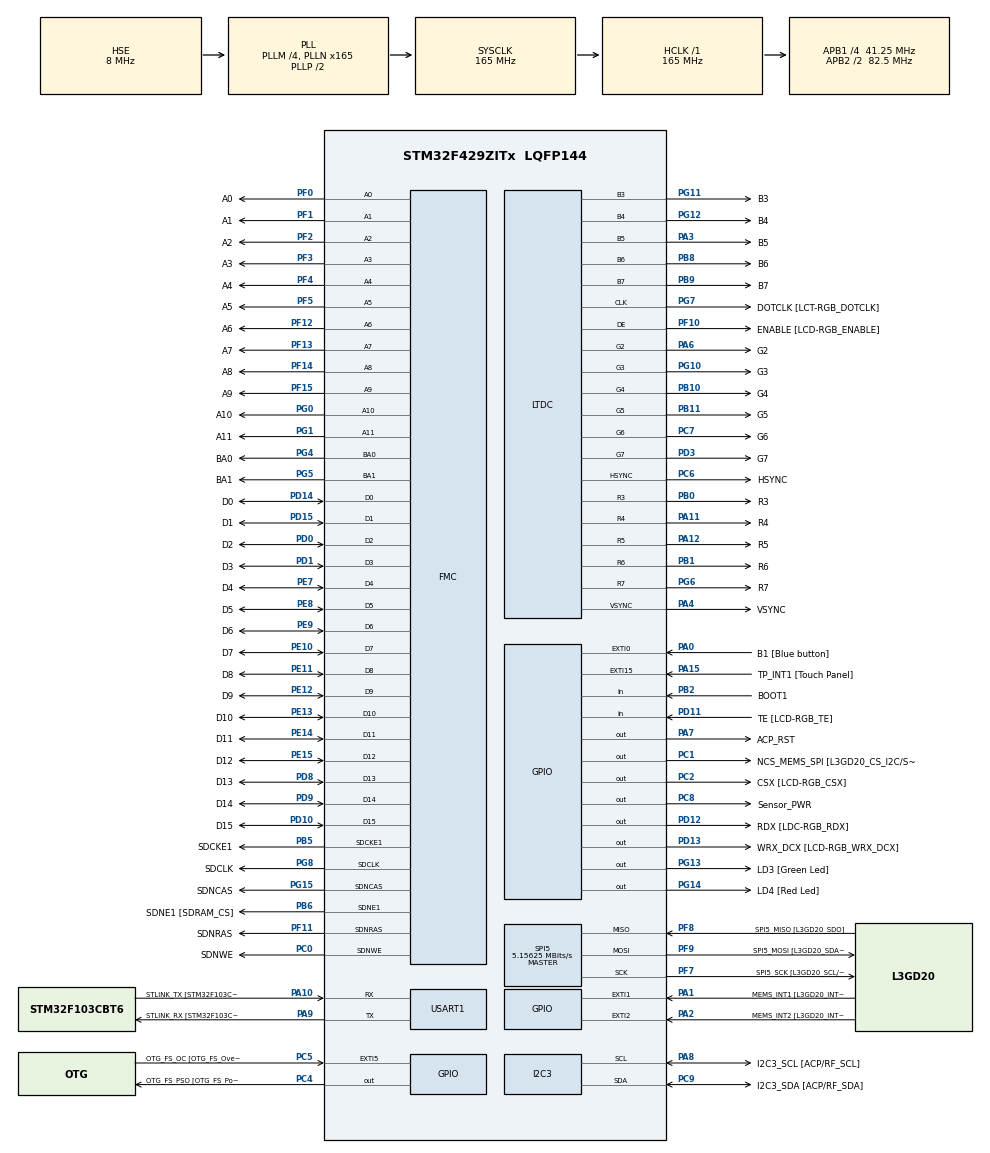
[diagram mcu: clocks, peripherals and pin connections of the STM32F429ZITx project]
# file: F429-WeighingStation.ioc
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Dma.I2C3_RX.0.Direction=DMA_PERIPH_TO_MEMORY
Dma.I2C3_RX.0.FIFOMode=DMA_FIFOMODE_DISABLE
Dma.I2C3_RX.0.Instance=DMA1_Stream2
Dma.I2C3_RX.0.MemDataAlignment=DMA_MDATAALIGN_BYTE
Dma.I2C3_RX.0.MemInc=DMA_MINC_ENABLE
Dma.I2C3_RX.0.Mode=DMA_NORMAL
Dma.I2C3_RX.0.PeriphDataAlignment=DMA_PDATAALIGN_BYTE
Dma.I2C3_RX.0.PeriphInc=DMA_PINC_DISABLE
Dma.I2C3_RX.0.Priority=DMA_PRIORITY_LOW
Dma.I2C3_TX.1.Direction=DMA_MEMORY_TO_PERIPH
Dma.I2C3_TX.1.FIFOMode=DMA_FIFOMODE_DISABLE
Dma.I2C3_TX.1.Instance=DMA1_Stream4
Dma.I2C3_TX.1.MemDataAlignment=DMA_MDATAALIGN_BYTE
Dma.I2C3_TX.1.MemInc=DMA_MINC_ENABLE
Dma.I2C3_TX.1.Mode=DMA_NORMAL
Dma.I2C3_TX.1.PeriphDataAlignment=DMA_PDATAALIGN_BYTE
Dma.I2C3_TX.1.PeriphInc=DMA_PINC_DISABLE
Dma.I2C3_TX.1.Priority=DMA_PRIORITY_LOW
Dma.Request0=I2C3_RX
Dma.Request1=I2C3_TX
Dma.Request2=USART1_RX
Dma.Request3=USART1_TX
Dma.USART1_RX.2.Direction=DMA_PERIPH_TO_MEMORY
Dma.USART1_RX.2.FIFOMode=DMA_FIFOMODE_DISABLE
Dma.USART1_RX.2.Instance=DMA2_Stream2
Dma.USART1_RX.2.MemDataAlignment=DMA_MDATAALIGN_BYTE
Dma.USART1_RX.2.MemInc=DMA_MINC_ENABLE
Dma.USART1_RX.2.Mode=DMA_CIRCULAR
Dma.USART1_RX.2.PeriphDataAlignment=DMA_PDATAALIGN_BYTE
Dma.USART1_RX.2.PeriphInc=DMA_PINC_DISABLE
Dma.USART1_RX.2.Priority=DMA_PRIORITY_MEDIUM
Dma.USART1_TX.3.Direction=DMA_MEMORY_TO_PERIPH
Dma.USART1_TX.3.FIFOMode=DMA_FIFOMODE_DISABLE
Dma.USART1_TX.3.Instance=DMA2_Stream7
Dma.USART1_TX.3.MemDataAlignment=DMA_MDATAALIGN_BYTE
Dma.USART1_TX.3.MemInc=DMA_MINC_ENABLE
Dma.USART1_TX.3.Mode=DMA_NORMAL
Dma.USART1_TX.3.PeriphDataAlignment=DMA_PDATAALIGN_BYTE
Dma.USART1_TX.3.PeriphInc=DMA_PINC_DISABLE
Dma.USART1_TX.3.Priority=DMA_PRIORITY_LOW
FMC.CASLatency1=FMC_SDRAM_CAS_LATENCY_3
FMC.ExitSelfRefreshDelay1=7
FMC.LoadToActiveDelay1=2
FMC.RCDDelay1=2
FMC.RPDelay1=2
FMC.ReadPipeDelay1=FMC_SDRAM_RPIPE_DELAY_1
FMC.RowCycleDelay1=7
FMC.SDClockPeriod1=FMC_SDRAM_CLOCK_PERIOD_2
FMC.SelfRefreshTime1=4
FMC.WriteRecoveryTime1=3
FREERTOS.INCLUDE_xTaskGetCurrentTaskHandle=1
FREERTOS.Tasks01=defaultTask,0,4096,StartDefaultTask,Default,NULL,Dynamic,NULL,NULL;grabI2CTask,-3,512,StartTaskI2C,Default,NULL,Dynamic,NULL,NULL;readI2CTask,0,512,readI2C,Default,NULL,Dynamic,NULL,NULL
FREERTOS.configCHECK_FOR_STACK_OVERFLOW=2
FREERTOS.configENABLE_BACKWARD_COMPATIBILITY=0
FREERTOS.configMINIMAL_STACK_SIZE=512
FREERTOS.configTOTAL_HEAP_SIZE=65536
FREERTOS.configUSE_APPLICATION_TASK_TAG=0
FREERTOS.configUSE_COUNTING_SEMAPHORES=0
FREERTOS.configUSE_IDLE_HOOK=0
FREERTOS.configUSE_MALLOC_FAILED_HOOK=1
FREERTOS.configUSE_RECURSIVE_MUTEXES=0
I2C3.AddressingMode=I2C_ADDRESSINGMODE_7BIT
I2C3.DutyCycle=I2C_DUTYCYCLE_16_9
I2C3.I2C_Mode=I2C_Fast
I2C3.OwnAddress=0x7E
LTDC.ActiveH=320
LTDC.ActiveW=240
LTDC.Alpha_L0=255
LTDC.BlendingFactor1_L0=LTDC_BLENDING_FACTOR1_PAxCA
LTDC.BlendingFactor2_L0=LTDC_BLENDING_FACTOR2_PAxCA
LTDC.FBStartAdress_L0=0xD0000000
LTDC.HBP=20
LTDC.HFP=10
LTDC.HSync=10
LTDC.ImageHeight_L0=320
LTDC.ImageWidth_L0=240
LTDC.Layers=0
LTDC.PixelFormat_L0=LTDC_PIXEL_FORMAT_RGB565
LTDC.VFP=4
LTDC.VSync=2
LTDC.WindowX1_L0=240
LTDC.WindowY1_L0=320
Mcu.Family=STM32F4
Mcu.Name=STM32F429ZITx
Mcu.Package=LQFP144
NVIC.DMA1_Stream2_IRQn=true\:5\:0\:false\:false\:true\:true\:false\:true
NVIC.DMA1_Stream4_IRQn=true\:5\:0\:false\:false\:true\:true\:false\:true
NVIC.DMA2_Stream2_IRQn=true\:5\:0\:true\:false\:true\:true\:false\:true
NVIC.DMA2_Stream7_IRQn=true\:5\:0\:true\:false\:true\:true\:false\:true
NVIC.EXTI0_IRQn=true\:5\:0\:false\:false\:true\:true\:true\:true
NVIC.I2C3_ER_IRQn=true\:5\:0\:false\:false\:true\:true\:true\:true
NVIC.I2C3_EV_IRQn=true\:5\:0\:false\:false\:true\:true\:true\:true
NVIC.LTDC_IRQn=true\:5\:0\:false\:false\:true\:true\:true\:true
NVIC.PriorityGroup=NVIC_PRIORITYGROUP_4
NVIC.TIM6_DAC_IRQn=true\:0\:0\:false\:false\:true\:false\:false\:true
NVIC.TimeBase=TIM6_DAC_IRQn
NVIC.TimeBaseIP=TIM6
NVIC.USART1_IRQn=true\:5\:0\:true\:false\:true\:false\:true\:true
PA0/WKUP.GPIO_Label=B1 [Blue button]
PA0/WKUP.Signal=GPXTI0
PA1.GPIO_Label=MEMS_INT1 [L3GD20_INT1]
PA1.GPIO_ModeDefaultEXTI=GPIO_MODE_EVT_RISING
PA1.GPIO_PuPd=GPIO_NOPULL
PA1.Signal=GPXTI1
PA10.GPIO_Label=STLINK_TX [STM32F103CBT6_PA2]
PA10.Mode=Asynchronous
PA10.Signal=USART1_RX
PA11.GPIO_Label=R4
PA11.GPIO_Mode=GPIO_MODE_AF_PP
PA11.GPIO_PuPd=GPIO_NOPULL
PA11.GPIO_Speed=GPIO_SPEED_FREQ_LOW
PA11.Mode=RGB565
PA11.Signal=LTDC_R4
PA12.GPIO_Label=R5
PA12.GPIO_Mode=GPIO_MODE_AF_PP
PA12.GPIO_PuPd=GPIO_NOPULL
PA12.GPIO_Speed=GPIO_SPEED_FREQ_LOW
PA12.Mode=RGB565
PA12.Signal=LTDC_R5
PA13.GPIO_Label=SWDIO
PA13.Mode=Serial_Wire
PA13.Signal=SYS_JTMS-SWDIO
PA14.GPIO_Label=SWCLK
PA14.Mode=Serial_Wire
PA14.Signal=SYS_JTCK-SWCLK
PA15.GPIO_Label=TP_INT1 [Touch Panel]
PA15.GPIO_ModeDefaultEXTI=GPIO_MODE_EVT_RISING
PA15.GPIO_PuPd=GPIO_NOPULL
PA15.Signal=GPXTI15
PA2.GPIO_Label=MEMS_INT2 [L3GD20_INT2]
PA2.GPIO_ModeDefaultEXTI=GPIO_MODE_EVT_RISING
PA2.GPIO_PuPd=GPIO_NOPULL
PA2.Signal=GPXTI2
PA3.GPIO_Label=B5
PA3.GPIO_Mode=GPIO_MODE_AF_PP
PA3.GPIO_PuPd=GPIO_NOPULL
PA3.GPIO_Speed=GPIO_SPEED_FREQ_LOW
PA3.Mode=RGB565
PA3.Signal=LTDC_B5
PA4.GPIO_Label=VSYNC
PA4.GPIO_Mode=GPIO_MODE_AF_PP
PA4.GPIO_PuPd=GPIO_NOPULL
PA4.GPIO_Speed=GPIO_SPEED_FREQ_LOW
PA4.Mode=RGB565
PA4.Signal=LTDC_VSYNC
PA6.GPIO_Label=G2
PA6.GPIO_Mode=GPIO_MODE_AF_PP
PA6.GPIO_PuPd=GPIO_NOPULL
PA6.GPIO_Speed=GPIO_SPEED_FREQ_LOW
PA6.Mode=RGB565
PA6.Signal=LTDC_G2
PA7.GPIO_Label=ACP_RST
PA7.GPIO_Mode=GPIO_MODE_OUTPUT_PP
PA7.GPIO_PuPd=GPIO_NOPULL
PA7.GPIO_Speed=GPIO_SPEED_FREQ_LOW
PA7.Signal=GPIO_Output
PA8.GPIO_Label=I2C3_SCL [ACP/RF_SCL]
PA8.GPIO_Mode=GPIO_MODE_AF_OD
PA8.GPIO_PuPd=GPIO_NOPULL
PA8.GPIO_Speed=GPIO_SPEED_FREQ_LOW
PA8.Mode=I2C
PA8.Signal=I2C3_SCL
PA9.GPIO_Label=STLINK_RX [STM32F103CBT6_PA3]
PA9.Mode=Asynchronous
PA9.Signal=USART1_TX
PB0.GPIO_Label=R3
PB0.GPIO_Mode=GPIO_MODE_AF_PP
PB0.GPIO_PuPd=GPIO_NOPULL
PB0.GPIO_Speed=GPIO_SPEED_FREQ_LOW
PB0.Mode=RGB565
PB0.Signal=LTDC_R3
PB1.GPIO_Label=R6
PB1.GPIO_Mode=GPIO_MODE_AF_PP
PB1.GPIO_PuPd=GPIO_NOPULL
PB1.GPIO_Speed=GPIO_SPEED_FREQ_LOW
PB1.Mode=RGB565
PB1.Signal=LTDC_R6
PB10.GPIO_Label=G4
PB10.GPIO_Mode=GPIO_MODE_AF_PP
PB10.GPIO_PuPd=GPIO_NOPULL
PB10.GPIO_Speed=GPIO_SPEED_FREQ_LOW
PB10.Mode=RGB565
PB10.Signal=LTDC_G4
PB11.GPIO_Label=G5
PB11.GPIO_Mode=GPIO_MODE_AF_PP
PB11.GPIO_PuPd=GPIO_NOPULL
PB11.GPIO_Speed=GPIO_SPEED_FREQ_LOW
PB11.Mode=RGB565
PB11.Signal=LTDC_G5
PB12.GPIO_Label=OTG_HS_ID
PB12.GPIO_Mode=GPIO_MODE_AF_PP
PB12.GPIO_PuPd=GPIO_NOPULL
PB12.GPIO_Speed=GPIO_SPEED_FREQ_LOW
PB12.Signal=USB_OTG_HS_ID
PB13.GPIO_Label=VBUS_HS
PB13.GPIO_Mode=GPIO_MODE_INPUT
PB13.GPIO_PuPd=GPIO_NOPULL
PB13.Signal=USB_OTG_HS_VBUS
PB14.GPIO_Label=OTG_HS_DM
PB14.GPIO_Mode=GPIO_MODE_AF_PP
PB14.GPIO_PuPd=GPIO_NOPULL
PB14.GPIO_Speed=GPIO_SPEED_FREQ_LOW
PB14.Signal=USB_OTG_HS_DM
PB15.GPIO_Label=OTG_HS_DP
PB15.GPIO_Mode=GPIO_MODE_AF_PP
PB15.GPIO_PuPd=GPIO_NOPULL
PB15.GPIO_Speed=GPIO_SPEED_FREQ_LOW
PB15.Signal=USB_OTG_HS_DP
PB2/BOOT1.GPIO_Label=BOOT1
PB2/BOOT1.GPIO_Mode=GPIO_MODE_INPUT
PB2/BOOT1.GPIO_PuPd=GPIO_NOPULL
PB2/BOOT1.Signal=GPIO_Input
PB5.GPIO_Label=SDCKE1
PB5.GPIO_Mode=GPIO_MODE_AF_PP
PB5.GPIO_PuPd=GPIO_NOPULL
PB5.GPIO_Speed=GPIO_SPEED_FREQ_VERY_HIGH
PB5.Mode=SdramChipSelect2_1
PB5.Signal=FMC_SDCKE1
PB6.GPIO_Label=SDNE1 [SDRAM_CS]
PB6.GPIO_Mode=GPIO_MODE_AF_PP
PB6.GPIO_PuPd=GPIO_NOPULL
PB6.GPIO_Speed=GPIO_SPEED_FREQ_VERY_HIGH
PB6.Mode=SdramChipSelect2_1
PB6.Signal=FMC_SDNE1
PB8.GPIO_Label=B6
PB8.GPIO_Mode=GPIO_MODE_AF_PP
PB8.GPIO_PuPd=GPIO_NOPULL
PB8.GPIO_Speed=GPIO_SPEED_FREQ_LOW
PB8.Mode=RGB565
PB8.Signal=LTDC_B6
PB9.GPIO_Label=B7
PB9.GPIO_Mode=GPIO_MODE_AF_PP
PB9.GPIO_PuPd=GPIO_NOPULL
PB9.GPIO_Speed=GPIO_SPEED_FREQ_LOW
PB9.Mode=RGB565
PB9.Signal=LTDC_B7
PC0.GPIO_Label=SDNWE
PC0.GPIO_Mode=GPIO_MODE_AF_PP
PC0.GPIO_PuPd=GPIO_NOPULL
PC0.GPIO_Speed=GPIO_SPEED_FREQ_VERY_HIGH
PC0.Signal=FMC_SDNWE
PC1.GPIO_Label=NCS_MEMS_SPI [L3GD20_CS_I2C/SPI]
PC1.GPIO_Mode=GPIO_MODE_OUTPUT_PP
PC1.GPIO_PuPd=GPIO_NOPULL
PC1.GPIO_Speed=GPIO_SPEED_FREQ_LOW
PC1.Signal=GPIO_Output
PC10.GPIO_Label=R2
PC10.GPIO_Mode=GPIO_MODE_AF_PP
PC10.GPIO_PuPd=GPIO_NOPULL
PC10.GPIO_Speed=GPIO_SPEED_FREQ_LOW
PC10.Signal=LTDC_R2
PC14/OSC32_IN.GPIO_Label=PC14-OSC32_IN
PC14/OSC32_IN.Signal=RCC_OSC32_IN
PC15/OSC32_OUT.GPIO_Label=PC15-OSC32_OUT
PC15/OSC32_OUT.Signal=RCC_OSC32_OUT
PC2.GPIO_Label=CSX [LCD-RGB_CSX]
PC2.GPIO_Mode=GPIO_MODE_OUTPUT_PP
PC2.GPIO_PuPd=GPIO_NOPULL
PC2.GPIO_Speed=GPIO_SPEED_FREQ_LOW
PC2.Signal=GPIO_Output
PC4.GPIO_Label=OTG_FS_PSO [OTG_FS_PowerSwitchOn]
PC4.GPIO_Mode=GPIO_MODE_OUTPUT_PP
PC4.GPIO_PuPd=GPIO_NOPULL
PC4.GPIO_Speed=GPIO_SPEED_FREQ_LOW
PC4.Signal=GPIO_Output
PC5.GPIO_Label=OTG_FS_OC [OTG_FS_OverCurrent]
PC5.GPIO_ModeDefaultEXTI=GPIO_MODE_EVT_RISING
PC5.Signal=GPXTI5
PC6.GPIO_Label=HSYNC
PC6.GPIO_Mode=GPIO_MODE_AF_PP
PC6.GPIO_PuPd=GPIO_NOPULL
PC6.GPIO_Speed=GPIO_SPEED_FREQ_LOW
PC6.Mode=RGB565
PC6.Signal=LTDC_HSYNC
PC7.GPIO_Label=G6
PC7.GPIO_Mode=GPIO_MODE_AF_PP
PC7.GPIO_PuPd=GPIO_NOPULL
PC7.GPIO_Speed=GPIO_SPEED_FREQ_LOW
PC7.Mode=RGB565
PC7.Signal=LTDC_G6
PC8.GPIO_Label=Sensor_PWR
PC8.Signal=GPIO_Output
PC9.GPIO_Label=I2C3_SDA [ACP/RF_SDA]
PC9.GPIO_Mode=GPIO_MODE_AF_OD
PC9.GPIO_PuPd=GPIO_NOPULL
PC9.GPIO_Speed=GPIO_SPEED_FREQ_LOW
PC9.Mode=I2C
PC9.Signal=I2C3_SDA
PD0.GPIO_Label=D2
PD0.GPIO_Mode=GPIO_MODE_AF_PP
PD0.GPIO_PuPd=GPIO_NOPULL
PD0.GPIO_Speed=GPIO_SPEED_FREQ_VERY_HIGH
PD0.Signal=FMC_D2_DA2
PD1.GPIO_Label=D3
PD1.GPIO_Mode=GPIO_MODE_AF_PP
PD1.GPIO_PuPd=GPIO_NOPULL
PD1.GPIO_Speed=GPIO_SPEED_FREQ_VERY_HIGH
PD1.Signal=FMC_D3_DA3
PD10.GPIO_Label=D15
PD10.GPIO_Mode=GPIO_MODE_AF_PP
PD10.GPIO_PuPd=GPIO_NOPULL
PD10.GPIO_Speed=GPIO_SPEED_FREQ_VERY_HIGH
PD10.Signal=FMC_D15_DA15
PD11.GPIO_Label=TE [LCD-RGB_TE]
PD11.GPIO_Mode=GPIO_MODE_INPUT
PD11.GPIO_PuPd=GPIO_NOPULL
PD11.Signal=GPIO_Input
PD12.GPIO_Label=RDX [LDC-RGB_RDX]
PD12.GPIO_Mode=GPIO_MODE_OUTPUT_PP
PD12.GPIO_PuPd=GPIO_NOPULL
PD12.GPIO_Speed=GPIO_SPEED_FREQ_LOW
PD12.Signal=GPIO_Output
PD13.GPIO_Label=WRX_DCX [LCD-RGB_WRX_DCX]
PD13.GPIO_Mode=GPIO_MODE_OUTPUT_PP
PD13.GPIO_PuPd=GPIO_NOPULL
PD13.GPIO_Speed=GPIO_SPEED_FREQ_LOW
PD13.Signal=GPIO_Output
PD14.GPIO_Label=D0
PD14.GPIO_Mode=GPIO_MODE_AF_PP
PD14.GPIO_PuPd=GPIO_NOPULL
PD14.GPIO_Speed=GPIO_SPEED_FREQ_VERY_HIGH
PD14.Signal=FMC_D0_DA0
PD15.GPIO_Label=D1
PD15.GPIO_Mode=GPIO_MODE_AF_PP
PD15.GPIO_PuPd=GPIO_NOPULL
PD15.GPIO_Speed=GPIO_SPEED_FREQ_VERY_HIGH
PD15.Signal=FMC_D1_DA1
PD3.GPIO_Label=G7
PD3.GPIO_Mode=GPIO_MODE_AF_PP
PD3.GPIO_PuPd=GPIO_NOPULL
PD3.GPIO_Speed=GPIO_SPEED_FREQ_LOW
PD3.Mode=RGB565
PD3.Signal=LTDC_G7
PD6.GPIO_Label=B2
PD6.GPIO_Mode=GPIO_MODE_AF_PP
PD6.GPIO_PuPd=GPIO_NOPULL
PD6.GPIO_Speed=GPIO_SPEED_FREQ_LOW
PD6.Signal=LTDC_B2
PD8.GPIO_Label=D13
PD8.GPIO_Mode=GPIO_MODE_AF_PP
PD8.GPIO_PuPd=GPIO_NOPULL
PD8.GPIO_Speed=GPIO_SPEED_FREQ_VERY_HIGH
PD8.Signal=FMC_D13_DA13
PD9.GPIO_Label=D14
PD9.GPIO_Mode=GPIO_MODE_AF_PP
PD9.GPIO_PuPd=GPIO_NOPULL
PD9.GPIO_Speed=GPIO_SPEED_FREQ_VERY_HIGH
PD9.Signal=FMC_D14_DA14
PE0.GPIO_Label=NBL0 [SDRAM_LDQM]
PE0.GPIO_Mode=GPIO_MODE_AF_PP
PE0.GPIO_PuPd=GPIO_NOPULL
PE0.GPIO_Speed=GPIO_SPEED_FREQ_VERY_HIGH
PE0.Signal=FMC_NBL0
PE1.GPIO_Label=NBL1 [SDRAM_UDQM]
PE1.GPIO_Mode=GPIO_MODE_AF_PP
PE1.GPIO_PuPd=GPIO_NOPULL
PE1.GPIO_Speed=GPIO_SPEED_FREQ_VERY_HIGH
PE1.Signal=FMC_NBL1
PE10.GPIO_Label=D7
PE10.GPIO_Mode=GPIO_MODE_AF_PP
PE10.GPIO_PuPd=GPIO_NOPULL
PE10.GPIO_Speed=GPIO_SPEED_FREQ_VERY_HIGH
PE10.Signal=FMC_D7_DA7
PE11.GPIO_Label=D8
PE11.GPIO_Mode=GPIO_MODE_AF_PP
PE11.GPIO_PuPd=GPIO_NOPULL
PE11.GPIO_Speed=GPIO_SPEED_FREQ_VERY_HIGH
PE11.Signal=FMC_D8_DA8
PE12.GPIO_Label=D9
PE12.GPIO_Mode=GPIO_MODE_AF_PP
PE12.GPIO_PuPd=GPIO_NOPULL
PE12.GPIO_Speed=GPIO_SPEED_FREQ_VERY_HIGH
PE12.Signal=FMC_D9_DA9
PE13.GPIO_Label=D10
PE13.GPIO_Mode=GPIO_MODE_AF_PP
PE13.GPIO_PuPd=GPIO_NOPULL
PE13.GPIO_Speed=GPIO_SPEED_FREQ_VERY_HIGH
PE13.Signal=FMC_D10_DA10
PE14.GPIO_Label=D11
PE14.GPIO_Mode=GPIO_MODE_AF_PP
PE14.GPIO_PuPd=GPIO_NOPULL
PE14.GPIO_Speed=GPIO_SPEED_FREQ_VERY_HIGH
PE14.Signal=FMC_D11_DA11
PE15.GPIO_Label=D12
PE15.GPIO_Mode=GPIO_MODE_AF_PP
PE15.GPIO_PuPd=GPIO_NOPULL
PE15.GPIO_Speed=GPIO_SPEED_FREQ_VERY_HIGH
PE15.Signal=FMC_D12_DA12
PE7.GPIO_Label=D4
PE7.GPIO_Mode=GPIO_MODE_AF_PP
PE7.GPIO_PuPd=GPIO_NOPULL
PE7.GPIO_Speed=GPIO_SPEED_FREQ_VERY_HIGH
PE7.Signal=FMC_D4_DA4
PE8.GPIO_Label=D5
PE8.GPIO_Mode=GPIO_MODE_AF_PP
PE8.GPIO_PuPd=GPIO_NOPULL
PE8.GPIO_Speed=GPIO_SPEED_FREQ_VERY_HIGH
PE8.Signal=FMC_D5_DA5
PE9.GPIO_Label=D6
PE9.GPIO_Mode=GPIO_MODE_AF_PP
PE9.GPIO_PuPd=GPIO_NOPULL
PE9.GPIO_Speed=GPIO_SPEED_FREQ_VERY_HIGH
PE9.Signal=FMC_D6_DA6
PF0.GPIO_Label=A0
PF0.GPIO_Mode=GPIO_MODE_AF_PP
PF0.GPIO_PuPd=GPIO_NOPULL
PF0.GPIO_Speed=GPIO_SPEED_FREQ_VERY_HIGH
PF0.Signal=FMC_A0
PF1.GPIO_Label=A1
PF1.GPIO_Mode=GPIO_MODE_AF_PP
PF1.GPIO_PuPd=GPIO_NOPULL
PF1.GPIO_Speed=GPIO_SPEED_FREQ_VERY_HIGH
PF1.Signal=FMC_A1
PF10.GPIO_Label=ENABLE [LCD-RGB_ENABLE]
PF10.GPIO_Mode=GPIO_MODE_AF_PP
PF10.GPIO_PuPd=GPIO_NOPULL
PF10.GPIO_Speed=GPIO_SPEED_FREQ_LOW
PF10.Mode=RGB565
PF10.Signal=LTDC_DE
PF11.GPIO_Label=SDNRAS
PF11.GPIO_Mode=GPIO_MODE_AF_PP
PF11.GPIO_PuPd=GPIO_NOPULL
PF11.GPIO_Speed=GPIO_SPEED_FREQ_VERY_HIGH
PF11.Signal=FMC_SDNRAS
PF12.GPIO_Label=A6
PF12.GPIO_Mode=GPIO_MODE_AF_PP
PF12.GPIO_PuPd=GPIO_NOPULL
PF12.GPIO_Speed=GPIO_SPEED_FREQ_VERY_HIGH
PF12.Signal=FMC_A6
PF13.GPIO_Label=A7
PF13.GPIO_Mode=GPIO_MODE_AF_PP
PF13.GPIO_PuPd=GPIO_NOPULL
PF13.GPIO_Speed=GPIO_SPEED_FREQ_VERY_HIGH
PF13.Signal=FMC_A7
PF14.GPIO_Label=A8
PF14.GPIO_Mode=GPIO_MODE_AF_PP
PF14.GPIO_PuPd=GPIO_NOPULL
PF14.GPIO_Speed=GPIO_SPEED_FREQ_VERY_HIGH
PF14.Signal=FMC_A8
PF15.GPIO_Label=A9
PF15.GPIO_Mode=GPIO_MODE_AF_PP
PF15.GPIO_PuPd=GPIO_NOPULL
PF15.GPIO_Speed=GPIO_SPEED_FREQ_VERY_HIGH
PF15.Signal=FMC_A9
PF2.GPIO_Label=A2
PF2.GPIO_Mode=GPIO_MODE_AF_PP
PF2.GPIO_PuPd=GPIO_NOPULL
PF2.GPIO_Speed=GPIO_SPEED_FREQ_VERY_HIGH
PF2.Signal=FMC_A2
PF3.GPIO_Label=A3
PF3.GPIO_Mode=GPIO_MODE_AF_PP
PF3.GPIO_PuPd=GPIO_NOPULL
PF3.GPIO_Speed=GPIO_SPEED_FREQ_VERY_HIGH
PF3.Signal=FMC_A3
PF4.GPIO_Label=A4
PF4.GPIO_Mode=GPIO_MODE_AF_PP
PF4.GPIO_PuPd=GPIO_NOPULL
PF4.GPIO_Speed=GPIO_SPEED_FREQ_VERY_HIGH
PF4.Signal=FMC_A4
PF5.GPIO_Label=A5
PF5.GPIO_Mode=GPIO_MODE_AF_PP
PF5.GPIO_PuPd=GPIO_NOPULL
PF5.GPIO_Speed=GPIO_SPEED_FREQ_VERY_HIGH
PF5.Signal=FMC_A5
PF7.GPIO_Label=SPI5_SCK [L3GD20_SCL/SPC]
PF7.GPIO_Mode=GPIO_MODE_AF_PP
PF7.GPIO_PuPd=GPIO_NOPULL
PF7.GPIO_Speed=GPIO_SPEED_FREQ_LOW
PF7.Mode=Full_Duplex_Master
PF7.Signal=SPI5_SCK
PF8.GPIO_Label=SPI5_MISO [L3GD20_SDO]
PF8.GPIO_Mode=GPIO_MODE_AF_PP
PF8.GPIO_PuPd=GPIO_NOPULL
PF8.GPIO_Speed=GPIO_SPEED_FREQ_LOW
PF8.Mode=Full_Duplex_Master
PF8.Signal=SPI5_MISO
PF9.GPIO_Label=SPI5_MOSI [L3GD20_SDA/SDI/SDO]
PF9.GPIO_Mode=GPIO_MODE_AF_PP
PF9.GPIO_PuPd=GPIO_NOPULL
PF9.GPIO_Speed=GPIO_SPEED_FREQ_LOW
PF9.Mode=Full_Duplex_Master
PF9.Signal=SPI5_MOSI
PG0.GPIO_Label=A10
PG0.GPIO_Mode=GPIO_MODE_AF_PP
PG0.GPIO_PuPd=GPIO_NOPULL
PG0.GPIO_Speed=GPIO_SPEED_FREQ_VERY_HIGH
PG0.Signal=FMC_A10
PG1.GPIO_Label=A11
PG1.GPIO_Mode=GPIO_MODE_AF_PP
PG1.GPIO_PuPd=GPIO_NOPULL
PG1.GPIO_Speed=GPIO_SPEED_FREQ_VERY_HIGH
PG1.Signal=FMC_A11
PG10.GPIO_Label=G3
PG10.GPIO_Mode=GPIO_MODE_AF_PP
PG10.GPIO_PuPd=GPIO_NOPULL
PG10.GPIO_Speed=GPIO_SPEED_FREQ_LOW
PG10.Mode=RGB565
PG10.Signal=LTDC_G3
PG11.GPIO_Label=B3
PG11.GPIO_Mode=GPIO_MODE_AF_PP
PG11.GPIO_PuPd=GPIO_NOPULL
PG11.GPIO_Speed=GPIO_SPEED_FREQ_LOW
PG11.Mode=RGB565
PG11.Signal=LTDC_B3
PG12.GPIO_Label=B4
PG12.GPIO_Mode=GPIO_MODE_AF_PP
PG12.GPIO_PuPd=GPIO_NOPULL
PG12.GPIO_Speed=GPIO_SPEED_FREQ_LOW
PG12.Mode=RGB565
PG12.Signal=LTDC_B4
PG13.GPIO_Label=LD3 [Green Led]
PG13.GPIO_Mode=GPIO_MODE_OUTPUT_PP
PG13.GPIO_PuPd=GPIO_NOPULL
PG13.GPIO_Speed=GPIO_SPEED_FREQ_LOW
PG13.Signal=GPIO_Output
PG14.GPIO_Label=LD4 [Red Led]
PG14.GPIO_Mode=GPIO_MODE_OUTPUT_PP
PG14.GPIO_PuPd=GPIO_NOPULL
PG14.GPIO_Speed=GPIO_SPEED_FREQ_LOW
PG14.Signal=GPIO_Output
PG15.GPIO_Label=SDNCAS
PG15.GPIO_Mode=GPIO_MODE_AF_PP
PG15.GPIO_PuPd=GPIO_NOPULL
PG15.GPIO_Speed=GPIO_SPEED_FREQ_VERY_HIGH
PG15.Signal=FMC_SDNCAS
PG4.GPIO_Label=BA0
PG4.GPIO_Mode=GPIO_MODE_AF_PP
PG4.GPIO_PuPd=GPIO_NOPULL
PG4.GPIO_Speed=GPIO_SPEED_FREQ_VERY_HIGH
PG4.Signal=FMC_A14_BA0
PG5.GPIO_Label=BA1
PG5.GPIO_Mode=GPIO_MODE_AF_PP
PG5.GPIO_PuPd=GPIO_NOPULL
PG5.GPIO_Speed=GPIO_SPEED_FREQ_VERY_HIGH
PG5.Signal=FMC_A15_BA1
PG6.GPIO_Label=R7
PG6.GPIO_Mode=GPIO_MODE_AF_PP
PG6.GPIO_PuPd=GPIO_NOPULL
PG6.GPIO_Speed=GPIO_SPEED_FREQ_LOW
PG6.Mode=RGB565
PG6.Signal=LTDC_R7
PG7.GPIO_Label=DOTCLK [LCT-RGB_DOTCLK]
PG7.GPIO_Mode=GPIO_MODE_AF_PP
PG7.GPIO_PuPd=GPIO_NOPULL
PG7.GPIO_Speed=GPIO_SPEED_FREQ_LOW
PG7.Mode=RGB565
PG7.Signal=LTDC_CLK
PG8.GPIO_Label=SDCLK
PG8.GPIO_Mode=GPIO_MODE_AF_PP
PG8.GPIO_PuPd=GPIO_NOPULL
PG8.GPIO_Speed=GPIO_SPEED_FREQ_VERY_HIGH
PG8.Signal=FMC_SDCLK
PH0/OSC_IN.GPIO_Label=PH0-OSC_IN
PH0/OSC_IN.Mode=HSE-External-Oscillator
PH0/OSC_IN.Signal=RCC_OSC_IN
PH1/OSC_OUT.GPIO_Label=PH1-OSC_OUT
PH1/OSC_OUT.Mode=HSE-External-Oscillator
PH1/OSC_OUT.Signal=RCC_OSC_OUT
ProjectManager.HeapSize=0x200
ProjectManager.StackSize=0x400
ProjectManager.TargetToolchain=STM32CubeIDE
RCC.48MHZClocksFreq_Value=47142857.14285714
RCC.AHBFreq_Value=165000000
RCC.APB1CLKDivider=RCC_HCLK_DIV4
RCC.APB1Freq_Value=41250000
RCC.APB1TimFreq_Value=165000000
RCC.APB2CLKDivider=RCC_HCLK_DIV2
RCC.APB2Freq_Value=82500000
RCC.APB2TimFreq_Value=165000000
RCC.CortexFreq_Value=165000000
RCC.HCLKFreq_Value=165000000
RCC.HSE_VALUE=8000000
RCC.HSI_VALUE=16000000
RCC.LSE_VALUE=32768
RCC.PLLM=4
RCC.PLLN=165
RCC.PLLQ=7
RCC.PLLSAIN=50
RCC.PLLSourceVirtual=RCC_PLLSOURCE_HSE
RCC.PWREXT_OverDrive=PWREXT_OverDrive_ACTIVATED
RCC.PWR_Regulator_Voltage_Scale=PWR_REGULATOR_VOLTAGE_SCALE1
RCC.RCC_TIM_PRescaler_Selection=RCC_TIMPRES_ACTIVATED
RCC.SYSCLKFreq_VALUE=165000000
RCC.SYSCLKSource=RCC_SYSCLKSOURCE_PLLCLK
RCC.VCOOutputFreq_Value=330000000
SH.FMC_A0.0=FMC_A0,12b-sda1
SH.FMC_A1.0=FMC_A1,12b-sda1
SH.FMC_A10.0=FMC_A10,12b-sda1
SH.FMC_A11.0=FMC_A11,12b-sda1
SH.FMC_A14_BA0.0=FMC_BA0,FourSdramBanks1
SH.FMC_A15_BA1.0=FMC_BA1,FourSdramBanks1
SH.FMC_A2.0=FMC_A2,12b-sda1
SH.FMC_A3.0=FMC_A3,12b-sda1
SH.FMC_A4.0=FMC_A4,12b-sda1
SH.FMC_A5.0=FMC_A5,12b-sda1
SH.FMC_A6.0=FMC_A6,12b-sda1
SH.FMC_A7.0=FMC_A7,12b-sda1
SH.FMC_A8.0=FMC_A8,12b-sda1
SH.FMC_A9.0=FMC_A9,12b-sda1
SH.FMC_D0_DA0.0=FMC_D0,sd-16b-d1
SH.FMC_D10_DA10.0=FMC_D10,sd-16b-d1
SH.FMC_D11_DA11.0=FMC_D11,sd-16b-d1
SH.FMC_D12_DA12.0=FMC_D12,sd-16b-d1
SH.FMC_D13_DA13.0=FMC_D13,sd-16b-d1
SH.FMC_D14_DA14.0=FMC_D14,sd-16b-d1
SH.FMC_D15_DA15.0=FMC_D15,sd-16b-d1
SH.FMC_D1_DA1.0=FMC_D1,sd-16b-d1
SH.FMC_D2_DA2.0=FMC_D2,sd-16b-d1
SH.FMC_D3_DA3.0=FMC_D3,sd-16b-d1
SH.FMC_D4_DA4.0=FMC_D4,sd-16b-d1
SH.FMC_D5_DA5.0=FMC_D5,sd-16b-d1
SH.FMC_D6_DA6.0=FMC_D6,sd-16b-d1
SH.FMC_D7_DA7.0=FMC_D7,sd-16b-d1
SH.FMC_D8_DA8.0=FMC_D8,sd-16b-d1
SH.FMC_D9_DA9.0=FMC_D9,sd-16b-d1
SH.FMC_NBL0.0=FMC_NBL0
SH.FMC_NBL1.0=FMC_NBL1
SH.FMC_SDCLK.0=FMC_SDCLK,12b-sda1
SH.FMC_SDNCAS.0=FMC_SDNCAS,12b-sda1
SH.FMC_SDNRAS.0=FMC_SDNRAS,12b-sda1
SH.FMC_SDNWE.0=FMC_SDNWE,12b-sda1
SPI5.BaudRatePrescaler=SPI_BAUDRATEPRESCALER_16
SPI5.CalculateBaudRate=5.15625 MBits/s
SPI5.Direction=SPI_DIRECTION_2LINES
SPI5.Mode=SPI_MODE_MASTER
SPI5.VirtualType=VM_MASTER
USART1.VirtualMode=VM_ASYNC
VP_DMA2D_VS_DMA2D.Mode=DMA2D_Activate
VP_FREERTOS_VS_CMSIS_V1.Mode=CMSIS_V1
VP_SYS_VS_tim6.Mode=TIM6
VP_TIM1_VS_ClockSourceITR.Mode=TriggerSource_ITR1
VP_TIM1_VS_ControllerModeClock.Mode=Clock Mode
board=STM32F429I-DISC1

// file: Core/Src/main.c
/* USER CODE BEGIN Header */
/**
  ******************************************************************************
  * @file           : main.c
  * @brief          : Main program body
  ******************************************************************************
  * @attention
  *
  * <h2><center>&copy; Copyright (c) 2020 STMicroelectronics.
  * All rights reserved.</center></h2>
  *
  * This software component is licensed by ST under Ultimate Liberty license
  * SLA0044, the "License"; You may not use this file except in compliance with
  * the License. You may obtain a copy of the License at:
  *                             www.st.com/SLA0044
  *
  ******************************************************************************
  */
/* USER CODE END Header */
#include "main.h"
#include "cmsis_os.h"

/* USER CODE BEGIN Includes */
#include <stdio.h>
#include <stdarg.h>
#include <string.h>
#include "stm32f429i_discovery_lcd.h"
/* USER CODE END Includes */

DMA2D_HandleTypeDef hdma2d;

I2C_HandleTypeDef hi2c3;
DMA_HandleTypeDef hdma_i2c3_rx;
DMA_HandleTypeDef hdma_i2c3_tx;

LTDC_HandleTypeDef hltdc;

SPI_HandleTypeDef hspi5;

TIM_HandleTypeDef htim1;

UART_HandleTypeDef huart1;
DMA_HandleTypeDef hdma_usart1_rx;
DMA_HandleTypeDef hdma_usart1_tx;

SDRAM_HandleTypeDef hsdram1;

osThreadId defaultTaskHandle;
osThreadId grabI2CTaskHandle;
osThreadId readI2CTaskHandle;
/* USER CODE BEGIN PV */
uint8_t LCdev[4];
uint8_t LCcnt;
uint8_t bridgeValue[4 * 4];
uint16_t counts;
uint16_t errs;
uint16_t stale;
volatile unsigned int u1rc;
volatile unsigned int u1hrc;
volatile unsigned int u1tc;
volatile unsigned int u1htc;
volatile unsigned int u1ec;
volatile unsigned int u1ic;
unsigned char dbgBuf[256];
unsigned char input[64];
unsigned char u1tx[256];
unsigned char u1rx[64];
/* USER CODE END PV */

void SystemClock_Config(void);
static void MX_GPIO_Init(void);
static void MX_DMA_Init(void);
static void MX_DMA2D_Init(void);
static void MX_FMC_Init(void);
static void MX_I2C3_Init(void);
static void MX_LTDC_Init(void);
static void MX_SPI5_Init(void);
static void MX_TIM1_Init(void);
static void MX_USART1_UART_Init(void);
void StartDefaultTask(void const * argument);
void StartTaskI2C(void const * argument);
void readI2C(void const * argument);

/* USER CODE BEGIN PFP */
void my_printf(char *format, ...)
	_ATTRIBUTE ((__format__ (__printf__, 1, 2)));
HAL_StatusTypeDef read_cell(I2C_HandleTypeDef *h, uint8_t d, uint8_t a, uint8_t *dataBuf, const uint32_t I2C_Timeout);
HAL_StatusTypeDef powerup_and_read(I2C_HandleTypeDef *h, uint8_t d, uint8_t *dataBuf, const uint32_t I2C_Timeout);
HAL_StatusTypeDef write_word(I2C_HandleTypeDef *, uint8_t, uint8_t *, uint8_t, uint8_t, uint8_t, const uint32_t);
HAL_StatusTypeDef exit_command_mode(I2C_HandleTypeDef *, uint8_t, uint8_t *, const uint32_t);
/* USER CODE END PFP */

int main(void)
{

  /* MCU Configuration--------------------------------------------------------*/

  /* Reset of all peripherals, Initializes the Flash interface and the Systick. */
  HAL_Init();

  /* Configure the system clock */
  SystemClock_Config();

  /* USER CODE BEGIN SysInit */

  // !!!!!  Make sure MX_DMA_Init(); comes before the UARTS here below...
  // !!!!!  Get enough stack room for the tasks (set minimal stack size to 512 at this point)
  // !!!!!  Watch out about interrupt priorities for DMA and/or UARTs ... ??? not sure what is the real deal there
  //        but when 0 instead of 5 I get vTaskNotifyGiveFromISR freezing the system from the DMA completion callback...

  /* USER CODE END SysInit */

  /* Initialize all configured peripherals */
  MX_GPIO_Init();
  MX_DMA_Init();
  MX_DMA2D_Init();
  MX_FMC_Init();
  MX_I2C3_Init();
  MX_LTDC_Init();
  MX_SPI5_Init();
  MX_TIM1_Init();
  MX_USART1_UART_Init();

  /* Create the thread(s) */
  /* definition and creation of defaultTask */
  osThreadDef(defaultTask, StartDefaultTask, osPriorityNormal, 0, 4096);
  defaultTaskHandle = osThreadCreate(osThread(defaultTask), NULL);

  /* definition and creation of grabI2CTask */
  osThreadDef(grabI2CTask, StartTaskI2C, osPriorityIdle, 0, 512);
  grabI2CTaskHandle = osThreadCreate(osThread(grabI2CTask), NULL);

  /* definition and creation of readI2CTask */
  osThreadDef(readI2CTask, readI2C, osPriorityNormal, 0, 512);
  readI2CTaskHandle = osThreadCreate(osThread(readI2CTask), NULL);

  /* Start scheduler */
  osKernelStart();

  /* We should never get here as control is now taken by the scheduler */
  /* Infinite loop */
  while (1)
  {

  }
}

void SystemClock_Config(void)
{
  RCC_OscInitTypeDef RCC_OscInitStruct = {0};
  RCC_ClkInitTypeDef RCC_ClkInitStruct = {0};
  RCC_PeriphCLKInitTypeDef PeriphClkInitStruct = {0};

  /** Configure the main internal regulator output voltage
  */
  __HAL_RCC_PWR_CLK_ENABLE();
  __HAL_PWR_VOLTAGESCALING_CONFIG(PWR_REGULATOR_VOLTAGE_SCALE1);
  /** Initializes the RCC Oscillators according to the specified parameters
  * in the RCC_OscInitTypeDef structure.
  */
  RCC_OscInitStruct.OscillatorType = RCC_OSCILLATORTYPE_HSE;
  RCC_OscInitStruct.HSEState = RCC_HSE_ON;
  RCC_OscInitStruct.PLL.PLLState = RCC_PLL_ON;
  RCC_OscInitStruct.PLL.PLLSource = RCC_PLLSOURCE_HSE;
  RCC_OscInitStruct.PLL.PLLM = 4;
  RCC_OscInitStruct.PLL.PLLN = 165;
  RCC_OscInitStruct.PLL.PLLP = RCC_PLLP_DIV2;
  RCC_OscInitStruct.PLL.PLLQ = 7;
  if (HAL_RCC_OscConfig(&RCC_OscInitStruct) != HAL_OK)
  {
    Error_Handler();
  }
  /** Activate the Over-Drive mode
  */
  if (HAL_PWREx_EnableOverDrive() != HAL_OK)
  {
    Error_Handler();
  }
  /** Initializes the CPU, AHB and APB buses clocks
  */
  RCC_ClkInitStruct.ClockType = RCC_CLOCKTYPE_HCLK|RCC_CLOCKTYPE_SYSCLK
                              |RCC_CLOCKTYPE_PCLK1|RCC_CLOCKTYPE_PCLK2;
  RCC_ClkInitStruct.SYSCLKSource = RCC_SYSCLKSOURCE_PLLCLK;
  RCC_ClkInitStruct.AHBCLKDivider = RCC_SYSCLK_DIV1;
  RCC_ClkInitStruct.APB1CLKDivider = RCC_HCLK_DIV4;
  RCC_ClkInitStruct.APB2CLKDivider = RCC_HCLK_DIV2;

  if (HAL_RCC_ClockConfig(&RCC_ClkInitStruct, FLASH_LATENCY_5) != HAL_OK)
  {
    Error_Handler();
  }
  PeriphClkInitStruct.PeriphClockSelection = RCC_PERIPHCLK_LTDC|RCC_PERIPHCLK_TIM;
  PeriphClkInitStruct.PLLSAI.PLLSAIN = 50;
  PeriphClkInitStruct.PLLSAI.PLLSAIR = 2;
  PeriphClkInitStruct.PLLSAIDivR = RCC_PLLSAIDIVR_2;
  PeriphClkInitStruct.TIMPresSelection = RCC_TIMPRES_ACTIVATED;
  if (HAL_RCCEx_PeriphCLKConfig(&PeriphClkInitStruct) != HAL_OK)
  {
    Error_Handler();
  }
}

static void MX_DMA2D_Init(void)
{

  hdma2d.Instance = DMA2D;
  hdma2d.Init.Mode = DMA2D_M2M;
  hdma2d.Init.ColorMode = DMA2D_OUTPUT_ARGB8888;
  hdma2d.Init.OutputOffset = 0;
  hdma2d.LayerCfg[1].InputOffset = 0;
  hdma2d.LayerCfg[1].InputColorMode = DMA2D_INPUT_ARGB8888;
  hdma2d.LayerCfg[1].AlphaMode = DMA2D_NO_MODIF_ALPHA;
  hdma2d.LayerCfg[1].InputAlpha = 0;
  if (HAL_DMA2D_Init(&hdma2d) != HAL_OK)
  {
    Error_Handler();
  }
  if (HAL_DMA2D_ConfigLayer(&hdma2d, 1) != HAL_OK)
  {
    Error_Handler();
  }

}

static void MX_I2C3_Init(void)
{

  hi2c3.Instance = I2C3;
  hi2c3.Init.ClockSpeed = 400000;
  hi2c3.Init.DutyCycle = I2C_DUTYCYCLE_16_9;
  hi2c3.Init.OwnAddress1 = 252;
  hi2c3.Init.AddressingMode = I2C_ADDRESSINGMODE_7BIT;
  hi2c3.Init.DualAddressMode = I2C_DUALADDRESS_DISABLE;
  hi2c3.Init.OwnAddress2 = 0;
  hi2c3.Init.GeneralCallMode = I2C_GENERALCALL_DISABLE;
  hi2c3.Init.NoStretchMode = I2C_NOSTRETCH_DISABLE;
  if (HAL_I2C_Init(&hi2c3) != HAL_OK)
  {
    Error_Handler();
  }
  /** Configure Analogue filter
  */
  if (HAL_I2CEx_ConfigAnalogFilter(&hi2c3, I2C_ANALOGFILTER_ENABLE) != HAL_OK)
  {
    Error_Handler();
  }
  /** Configure Digital filter
  */
  if (HAL_I2CEx_ConfigDigitalFilter(&hi2c3, 0) != HAL_OK)
  {
    Error_Handler();
  }

}

static void MX_LTDC_Init(void)
{

  LTDC_LayerCfgTypeDef pLayerCfg = {0};
  LTDC_LayerCfgTypeDef pLayerCfg1 = {0};

  hltdc.Instance = LTDC;
  hltdc.Init.HSPolarity = LTDC_HSPOLARITY_AL;
  hltdc.Init.VSPolarity = LTDC_VSPOLARITY_AL;
  hltdc.Init.DEPolarity = LTDC_DEPOLARITY_AL;
  hltdc.Init.PCPolarity = LTDC_PCPOLARITY_IPC;
  hltdc.Init.HorizontalSync = 9;
  hltdc.Init.VerticalSync = 1;
  hltdc.Init.AccumulatedHBP = 29;
  hltdc.Init.AccumulatedVBP = 3;
  hltdc.Init.AccumulatedActiveW = 269;
  hltdc.Init.AccumulatedActiveH = 323;
  hltdc.Init.TotalWidth = 279;
  hltdc.Init.TotalHeigh = 327;
  hltdc.Init.Backcolor.Blue = 0;
  hltdc.Init.Backcolor.Green = 0;
  hltdc.Init.Backcolor.Red = 0;
  if (HAL_LTDC_Init(&hltdc) != HAL_OK)
  {
    Error_Handler();
  }
  pLayerCfg.WindowX0 = 0;
  pLayerCfg.WindowX1 = 240;
  pLayerCfg.WindowY0 = 0;
  pLayerCfg.WindowY1 = 320;
  pLayerCfg.PixelFormat = LTDC_PIXEL_FORMAT_RGB565;
  pLayerCfg.Alpha = 255;
  pLayerCfg.Alpha0 = 0;
  pLayerCfg.BlendingFactor1 = LTDC_BLENDING_FACTOR1_PAxCA;
  pLayerCfg.BlendingFactor2 = LTDC_BLENDING_FACTOR2_PAxCA;
  pLayerCfg.FBStartAdress = 0xD0000000;
  pLayerCfg.ImageWidth = 240;
  pLayerCfg.ImageHeight = 320;
  pLayerCfg.Backcolor.Blue = 0;
  pLayerCfg.Backcolor.Green = 0;
  pLayerCfg.Backcolor.Red = 0;
  if (HAL_LTDC_ConfigLayer(&hltdc, &pLayerCfg, 0) != HAL_OK)
  {
    Error_Handler();
  }
  pLayerCfg1.WindowX0 = 0;
  pLayerCfg1.WindowX1 = 0;
  pLayerCfg1.WindowY0 = 0;
  pLayerCfg1.WindowY1 = 0;
  pLayerCfg1.Alpha = 0;
  pLayerCfg1.Alpha0 = 0;
  pLayerCfg1.BlendingFactor1 = LTDC_BLENDING_FACTOR1_CA;
  pLayerCfg1.BlendingFactor2 = LTDC_BLENDING_FACTOR2_CA;
  pLayerCfg1.FBStartAdress = 0;
  pLayerCfg1.ImageWidth = 0;
  pLayerCfg1.ImageHeight = 0;
  pLayerCfg1.Backcolor.Blue = 0;
  pLayerCfg1.Backcolor.Green = 0;
  pLayerCfg1.Backcolor.Red = 0;
  if (HAL_LTDC_ConfigLayer(&hltdc, &pLayerCfg1, 1) != HAL_OK)
  {
    Error_Handler();
  }

}

static void MX_SPI5_Init(void)
{

  /* SPI5 parameter configuration*/
  hspi5.Instance = SPI5;
  hspi5.Init.Mode = SPI_MODE_MASTER;
  hspi5.Init.Direction = SPI_DIRECTION_2LINES;
  hspi5.Init.DataSize = SPI_DATASIZE_8BIT;
  hspi5.Init.CLKPolarity = SPI_POLARITY_LOW;
  hspi5.Init.CLKPhase = SPI_PHASE_1EDGE;
  hspi5.Init.NSS = SPI_NSS_SOFT;
  hspi5.Init.BaudRatePrescaler = SPI_BAUDRATEPRESCALER_16;
  hspi5.Init.FirstBit = SPI_FIRSTBIT_MSB;
  hspi5.Init.TIMode = SPI_TIMODE_DISABLE;
  hspi5.Init.CRCCalculation = SPI_CRCCALCULATION_DISABLE;
  hspi5.Init.CRCPolynomial = 10;
  if (HAL_SPI_Init(&hspi5) != HAL_OK)
  {
    Error_Handler();
  }

}

static void MX_TIM1_Init(void)
{

  TIM_SlaveConfigTypeDef sSlaveConfig = {0};
  TIM_MasterConfigTypeDef sMasterConfig = {0};

  htim1.Instance = TIM1;
  htim1.Init.Prescaler = 0;
  htim1.Init.CounterMode = TIM_COUNTERMODE_UP;
  htim1.Init.Period = 65535;
  htim1.Init.ClockDivision = TIM_CLOCKDIVISION_DIV1;
  htim1.Init.RepetitionCounter = 0;
  htim1.Init.AutoReloadPreload = TIM_AUTORELOAD_PRELOAD_DISABLE;
  if (HAL_TIM_Base_Init(&htim1) != HAL_OK)
  {
    Error_Handler();
  }
  sSlaveConfig.SlaveMode = TIM_SLAVEMODE_EXTERNAL1;
  sSlaveConfig.InputTrigger = TIM_TS_ITR1;
  if (HAL_TIM_SlaveConfigSynchro(&htim1, &sSlaveConfig) != HAL_OK)
  {
    Error_Handler();
  }
  sMasterConfig.MasterOutputTrigger = TIM_TRGO_RESET;
  sMasterConfig.MasterSlaveMode = TIM_MASTERSLAVEMODE_DISABLE;
  if (HAL_TIMEx_MasterConfigSynchronization(&htim1, &sMasterConfig) != HAL_OK)
  {
    Error_Handler();
  }

}

static void MX_USART1_UART_Init(void)
{

  huart1.Instance = USART1;
  huart1.Init.BaudRate = 115200;
  huart1.Init.WordLength = UART_WORDLENGTH_8B;
  huart1.Init.StopBits = UART_STOPBITS_1;
  huart1.Init.Parity = UART_PARITY_NONE;
  huart1.Init.Mode = UART_MODE_TX_RX;
  huart1.Init.HwFlowCtl = UART_HWCONTROL_NONE;
  huart1.Init.OverSampling = UART_OVERSAMPLING_16;
  if (HAL_UART_Init(&huart1) != HAL_OK)
  {
    Error_Handler();
  }

}

static void MX_DMA_Init(void)
{

  /* DMA controller clock enable */
  __HAL_RCC_DMA1_CLK_ENABLE();
  __HAL_RCC_DMA2_CLK_ENABLE();

  /* DMA interrupt init */
  /* DMA1_Stream2_IRQn interrupt configuration */
  HAL_NVIC_SetPriority(DMA1_Stream2_IRQn, 5, 0);
  HAL_NVIC_EnableIRQ(DMA1_Stream2_IRQn);
  /* DMA1_Stream4_IRQn interrupt configuration */
  HAL_NVIC_SetPriority(DMA1_Stream4_IRQn, 5, 0);
  HAL_NVIC_EnableIRQ(DMA1_Stream4_IRQn);
  /* DMA2_Stream2_IRQn interrupt configuration */
  HAL_NVIC_SetPriority(DMA2_Stream2_IRQn, 5, 0);
  HAL_NVIC_EnableIRQ(DMA2_Stream2_IRQn);
  /* DMA2_Stream7_IRQn interrupt configuration */
  HAL_NVIC_SetPriority(DMA2_Stream7_IRQn, 5, 0);
  HAL_NVIC_EnableIRQ(DMA2_Stream7_IRQn);

}

/* FMC initialization function */
static void MX_FMC_Init(void)
{

  FMC_SDRAM_TimingTypeDef SdramTiming = {0};

  /** Perform the SDRAM1 memory initialization sequence
  */
  hsdram1.Instance = FMC_SDRAM_DEVICE;
  /* hsdram1.Init */
  hsdram1.Init.SDBank = FMC_SDRAM_BANK2;
  hsdram1.Init.ColumnBitsNumber = FMC_SDRAM_COLUMN_BITS_NUM_8;
  hsdram1.Init.RowBitsNumber = FMC_SDRAM_ROW_BITS_NUM_12;
  hsdram1.Init.MemoryDataWidth = FMC_SDRAM_MEM_BUS_WIDTH_16;
  hsdram1.Init.InternalBankNumber = FMC_SDRAM_INTERN_BANKS_NUM_4;
  hsdram1.Init.CASLatency = FMC_SDRAM_CAS_LATENCY_3;
  hsdram1.Init.WriteProtection = FMC_SDRAM_WRITE_PROTECTION_DISABLE;
  hsdram1.Init.SDClockPeriod = FMC_SDRAM_CLOCK_PERIOD_2;
  hsdram1.Init.ReadBurst = FMC_SDRAM_RBURST_DISABLE;
  hsdram1.Init.ReadPipeDelay = FMC_SDRAM_RPIPE_DELAY_1;
  /* SdramTiming */
  SdramTiming.LoadToActiveDelay = 2;
  SdramTiming.ExitSelfRefreshDelay = 7;
  SdramTiming.SelfRefreshTime = 4;
  SdramTiming.RowCycleDelay = 7;
  SdramTiming.WriteRecoveryTime = 3;
  SdramTiming.RPDelay = 2;
  SdramTiming.RCDDelay = 2;

  if (HAL_SDRAM_Init(&hsdram1, &SdramTiming) != HAL_OK)
  {
    Error_Handler( );
  }

}

static void MX_GPIO_Init(void)
{
  GPIO_InitTypeDef GPIO_InitStruct = {0};

  /* GPIO Ports Clock Enable */
  __HAL_RCC_GPIOC_CLK_ENABLE();
  __HAL_RCC_GPIOF_CLK_ENABLE();
  __HAL_RCC_GPIOH_CLK_ENABLE();
  __HAL_RCC_GPIOA_CLK_ENABLE();
  __HAL_RCC_GPIOB_CLK_ENABLE();
  __HAL_RCC_GPIOG_CLK_ENABLE();
  __HAL_RCC_GPIOE_CLK_ENABLE();
  __HAL_RCC_GPIOD_CLK_ENABLE();

  /*Configure GPIO pin Output Level */
  HAL_GPIO_WritePin(GPIOC, NCS_MEMS_SPI_Pin|CSX_Pin|OTG_FS_PSO_Pin|Sensor_PWR_Pin, GPIO_PIN_RESET);

  /*Configure GPIO pin Output Level */
  HAL_GPIO_WritePin(ACP_RST_GPIO_Port, ACP_RST_Pin, GPIO_PIN_RESET);

  /*Configure GPIO pin Output Level */
  HAL_GPIO_WritePin(GPIOD, RDX_Pin|WRX_DCX_Pin, GPIO_PIN_RESET);

  /*Configure GPIO pin Output Level */
  HAL_GPIO_WritePin(GPIOG, LD3_Pin|LD4_Pin, GPIO_PIN_RESET);

  /*Configure GPIO pins : NCS_MEMS_SPI_Pin CSX_Pin OTG_FS_PSO_Pin Sensor_PWR_Pin */
  GPIO_InitStruct.Pin = NCS_MEMS_SPI_Pin|CSX_Pin|OTG_FS_PSO_Pin|Sensor_PWR_Pin;
  GPIO_InitStruct.Mode = GPIO_MODE_OUTPUT_PP;
  GPIO_InitStruct.Pull = GPIO_NOPULL;
  GPIO_InitStruct.Speed = GPIO_SPEED_FREQ_LOW;
  HAL_GPIO_Init(GPIOC, &GPIO_InitStruct);

  /*Configure GPIO pin : B1_Pin */
  GPIO_InitStruct.Pin = B1_Pin;
  GPIO_InitStruct.Mode = GPIO_MODE_IT_RISING;
  GPIO_InitStruct.Pull = GPIO_NOPULL;
  HAL_GPIO_Init(B1_GPIO_Port, &GPIO_InitStruct);

  /*Configure GPIO pins : MEMS_INT1_Pin MEMS_INT2_Pin TP_INT1_Pin */
  GPIO_InitStruct.Pin = MEMS_INT1_Pin|MEMS_INT2_Pin|TP_INT1_Pin;
  GPIO_InitStruct.Mode = GPIO_MODE_EVT_RISING;
  GPIO_InitStruct.Pull = GPIO_NOPULL;
  HAL_GPIO_Init(GPIOA, &GPIO_InitStruct);

  /*Configure GPIO pin : ACP_RST_Pin */
  GPIO_InitStruct.Pin = ACP_RST_Pin;
  GPIO_InitStruct.Mode = GPIO_MODE_OUTPUT_PP;
  GPIO_InitStruct.Pull = GPIO_NOPULL;
  GPIO_InitStruct.Speed = GPIO_SPEED_FREQ_LOW;
  HAL_GPIO_Init(ACP_RST_GPIO_Port, &GPIO_InitStruct);

  /*Configure GPIO pin : OTG_FS_OC_Pin */
  GPIO_InitStruct.Pin = OTG_FS_OC_Pin;
  GPIO_InitStruct.Mode = GPIO_MODE_EVT_RISING;
  GPIO_InitStruct.Pull = GPIO_NOPULL;
  HAL_GPIO_Init(OTG_FS_OC_GPIO_Port, &GPIO_InitStruct);

  /*Configure GPIO pin : BOOT1_Pin */
  GPIO_InitStruct.Pin = BOOT1_Pin;
  GPIO_InitStruct.Mode = GPIO_MODE_INPUT;
  GPIO_InitStruct.Pull = GPIO_NOPULL;
  HAL_GPIO_Init(BOOT1_GPIO_Port, &GPIO_InitStruct);

  /*Configure GPIO pins : OTG_HS_ID_Pin OTG_HS_DM_Pin OTG_HS_DP_Pin */
  GPIO_InitStruct.Pin = OTG_HS_ID_Pin|OTG_HS_DM_Pin|OTG_HS_DP_Pin;
  GPIO_InitStruct.Mode = GPIO_MODE_AF_PP;
  GPIO_InitStruct.Pull = GPIO_NOPULL;
  GPIO_InitStruct.Speed = GPIO_SPEED_FREQ_LOW;
  GPIO_InitStruct.Alternate = GPIO_AF12_OTG_HS_FS;
  HAL_GPIO_Init(GPIOB, &GPIO_InitStruct);

  /*Configure GPIO pin : VBUS_HS_Pin */
  GPIO_InitStruct.Pin = VBUS_HS_Pin;
  GPIO_InitStruct.Mode = GPIO_MODE_INPUT;
  GPIO_InitStruct.Pull = GPIO_NOPULL;
  HAL_GPIO_Init(VBUS_HS_GPIO_Port, &GPIO_InitStruct);

  /*Configure GPIO pin : TE_Pin */
  GPIO_InitStruct.Pin = TE_Pin;
  GPIO_InitStruct.Mode = GPIO_MODE_INPUT;
  GPIO_InitStruct.Pull = GPIO_NOPULL;
  HAL_GPIO_Init(TE_GPIO_Port, &GPIO_InitStruct);

  /*Configure GPIO pins : RDX_Pin WRX_DCX_Pin */
  GPIO_InitStruct.Pin = RDX_Pin|WRX_DCX_Pin;
  GPIO_InitStruct.Mode = GPIO_MODE_OUTPUT_PP;
  GPIO_InitStruct.Pull = GPIO_NOPULL;
  GPIO_InitStruct.Speed = GPIO_SPEED_FREQ_LOW;
  HAL_GPIO_Init(GPIOD, &GPIO_InitStruct);

  /*Configure GPIO pins : LD3_Pin LD4_Pin */
  GPIO_InitStruct.Pin = LD3_Pin|LD4_Pin;
  GPIO_InitStruct.Mode = GPIO_MODE_OUTPUT_PP;
  GPIO_InitStruct.Pull = GPIO_NOPULL;
  GPIO_InitStruct.Speed = GPIO_SPEED_FREQ_LOW;
  HAL_GPIO_Init(GPIOG, &GPIO_InitStruct);

  /* EXTI interrupt init*/
  HAL_NVIC_SetPriority(EXTI0_IRQn, 5, 0);
  HAL_NVIC_EnableIRQ(EXTI0_IRQn);

}

/* USER CODE BEGIN 4 */
void HAL_UART_TxCpltCallback(UART_HandleTypeDef *huart)
{
	BaseType_t xHigherPriorityTaskWoken = pdFALSE;

	HAL_GPIO_TogglePin(LD4_GPIO_Port, LD4_Pin); // toggle red led

	if (huart->Instance == USART1)
	{
		u1tc += 1;
		/* Notify the task that the transmission is complete. */
    vTaskNotifyGiveFromISR(grabI2CTaskHandle, &xHigherPriorityTaskWoken);
    portYIELD_FROM_ISR(xHigherPriorityTaskWoken);
	}
}

void HAL_UART_TxHalfCpltCallback(UART_HandleTypeDef *huart)
{
	if (huart->Instance == USART1)
		u1htc += 1;
}

void HAL_UART_RxCpltCallback(UART_HandleTypeDef *huart)
{
	if (huart->Instance == USART1)
		u1rc += 1;
}

void HAL_UART_RxHalfCpltCallback(UART_HandleTypeDef *huart)
{
	if (huart->Instance == USART1)
		u1hrc += 1;
}

void HAL_UART_ErrorCallback(UART_HandleTypeDef *huart)
{
	if (huart->Instance == USART1)
		u1ec += 1;
}

void HAL_GPIO_EXTI_Callback(uint16_t GPIO_Pin)
{
	if (GPIO_Pin == B1_Pin)
	{
		HAL_GPIO_TogglePin(LD3_GPIO_Port, LD3_Pin);
	}
}

#if 0
void HAL_I2C_MasterRxCpltCallback(I2C_HandleTypeDef *hi2c)
{
	if (hi2c == &hi2c3)
	{
		HAL_GPIO_TogglePin(LD4_GPIO_Port, LD4_Pin);
		memcpy(bridgeValue,dataBuf,2);
	}
}
#endif

int UART_Receive(unsigned char *dest, const unsigned char *rx, UART_HandleTypeDef *huart, unsigned int *uxcc, const unsigned int max)
{
	unsigned int cc = __HAL_DMA_GET_COUNTER(huart->hdmarx);
	if (*uxcc != cc)
	{
		HAL_UART_DMAPause(huart);
  	int len = 0;
		if (cc > *uxcc)
		{
			for (unsigned int i = max - *uxcc; i < max; i++)
				dest[len++] = rx[i];
			for (unsigned int i = 0; i < max - cc; i++)
				dest[len++] = rx[i];
		}
		else
		{
			for (unsigned int i = max - *uxcc; i < max - cc; i++)
				dest[len++] = rx[i];
		}
		HAL_UART_DMAResume(huart);
  	*uxcc = cc;
  	return len;
	}
	return 0;
}

void my_printf(char *format, ...)
{
	va_list args;
	const TickType_t xMaxBlockTime = pdMS_TO_TICKS( 200 );
	uint32_t ulNotificationValue;
	HAL_StatusTypeDef res;
	va_start(args, format);
	int len = vsniprintf((char *) dbgBuf, 256, format, args);
	va_end(args);
	res = HAL_UART_Transmit_DMA(&huart1, dbgBuf, len);
	ulNotificationValue = ulTaskNotifyTake(pdTRUE, xMaxBlockTime);
	if (res != HAL_OK || ulNotificationValue != 1)
	{
		/* Something went wrong during output... */
		//HAL_UART_DMAStop(&huart1);
		errs += 8;
		HAL_GPIO_TogglePin(LD3_GPIO_Port, LD3_Pin); // toggle green led
		len = snprintf((char *) dbgBuf, 256, "Timeout waiting on the DMA completion for %u ticks - seems bad\r\n", 200);
		HAL_UART_Transmit(&huart1, dbgBuf, len, xMaxBlockTime);
	}
}

HAL_StatusTypeDef read_cell(I2C_HandleTypeDef *h, uint8_t d, uint8_t a, uint8_t *dataBuf, const uint32_t I2C_Timeout)
{
	dataBuf[0] = a;
	dataBuf[1] = 0;
	dataBuf[2] = 0;
	HAL_I2C_Master_Transmit(h, d, dataBuf, 3, I2C_Timeout);
	memset(dataBuf, 0, 3);
	return HAL_I2C_Master_Receive(h, d | 1, dataBuf, 3, I2C_Timeout);
}

HAL_StatusTypeDef powerup_and_read(I2C_HandleTypeDef *h, uint8_t d, uint8_t *dataBuf, const uint32_t I2C_Timeout)
{
	dataBuf[0] = 0xA0;
	dataBuf[1] = 0;
	dataBuf[2] = 0;
	HAL_GPIO_WritePin(GPIOC, Sensor_PWR_Pin, GPIO_PIN_SET);
	HAL_Delay(3);
	HAL_I2C_Master_Transmit(h, d, dataBuf, 3, I2C_Timeout);
	return read_cell(h, d, 2, dataBuf, I2C_Timeout);
}

HAL_StatusTypeDef write_word(I2C_HandleTypeDef *h, uint8_t d, uint8_t *dataBuf, uint8_t a, uint8_t d1, uint8_t d2, const uint32_t I2C_Timeout)
{
	dataBuf[0] = 0x40 | a;
	dataBuf[1] = d1;
	dataBuf[2] = d2;
	my_printf("Sending 0x%02X 0x%02X 0x%02X\r\n", dataBuf[0], dataBuf[1], dataBuf[2]);
	HAL_StatusTypeDef res = HAL_I2C_Master_Transmit(h, d, dataBuf, 3, I2C_Timeout);
	my_printf("HAL res after send word %u = %d\r\n", (int) a, res);
	HAL_Delay(15); // wait 15 ms according to DS
	return res;
}

HAL_StatusTypeDef exit_command_mode(I2C_HandleTypeDef *h, uint8_t d, uint8_t *dataBuf, const uint32_t I2C_Timeout)
{
	dataBuf[0] = 0x80;
	dataBuf[1] = 0;
	dataBuf[2] = 0;
	HAL_StatusTypeDef res = HAL_I2C_Master_Transmit(&hi2c3, d, dataBuf, 3, I2C_Timeout);
	my_printf("HAL res after send exit command mode = %d\r\n", res);
	HAL_Delay(15); // wait another 15 ms to update EEPROM signature
	return res;
}
/* USER CODE END 4 */

void StartDefaultTask(void const * argument)
{
  /* USER CODE BEGIN 5 */
	const uint32_t low = 950;
	uint16_t c = 0;
	BSP_LCD_Init();
	/* Initialize the LCD Layers */
	BSP_LCD_LayerDefaultInit(1, LCD_FRAME_BUFFER);
	/* Set LCD Foreground Layer  */
	BSP_LCD_SelectLayer(1);
	BSP_LCD_SetFont(&LCD_DEFAULT_FONT);
	/* Clear the LCD */
	BSP_LCD_SetBackColor(LCD_COLOR_BLACK);
	BSP_LCD_Clear(LCD_COLOR_BLACK);
	/* Set the LCD Text Color */
	BSP_LCD_SetTextColor(LCD_COLOR_GREEN);

	/* Display LCD messages */
	BSP_LCD_DisplayStringAt(0, 10, (uint8_t*)"STM32F429I BSP", CENTER_MODE);
	BSP_LCD_SetFont(&Font16);
	BSP_LCD_DisplayStringAt(0, 35, (uint8_t*)"Weighing Station", CENTER_MODE);
	BSP_LCD_SetFont(&Font20);
	HAL_GPIO_WritePin(LD3_GPIO_Port, LD3_Pin, GPIO_PIN_SET);
  /* Infinite loop */
	for(;;)
	{
		uint8_t msg[50];
		sprintf((char *)msg,"%u %u %u %u",c,errs,counts,stale);
		BSP_LCD_DisplayStringAt(0, BSP_LCD_GetYSize()/2, msg, CENTER_MODE);
		sprintf((char *)msg,"%02x %02x %02x %02x",bridgeValue[0],bridgeValue[1],bridgeValue[2],bridgeValue[3]);
		BSP_LCD_DisplayStringAt(0, BSP_LCD_GetYSize()/2 + 35, msg, CENTER_MODE);
		uint32_t weight = (bridgeValue[0] & 0x3f) * 256 + bridgeValue[1];
		sprintf((char *)msg,"  raw : %ld  ", weight);
		BSP_LCD_DisplayStringAt(0, BSP_LCD_GetYSize()/2 + 75, msg, CENTER_MODE);
		if (weight < low)
			weight = 0;
		else
			weight -= low;
		weight *= 5000;
		weight /= 14000;
		sprintf((char *)msg,"W: %2d.%02d kg", (uint16_t)(weight / 100), (uint16_t)(weight % 100));
		BSP_LCD_DisplayStringAt(0, BSP_LCD_GetYSize()/2 + 55, msg, CENTER_MODE);
		// Try this : Temperature = (Counts x 200 / 2048) - 50
		/*
		 * Temperature Output vs Counts
		 * Output oC  Digital Counts (decimal)  Digital  Counts (hex)
		 *   -50                0                    0 x 0000
		 *     0              512                    0 X 0200
		 *    10              614                    0 X 0266
		 *    25              767                    0 X 02FF
		 *    40              921                    0 X 0399
		 *    85             1381                    0 X 0565
		 *   150             2047                    0 X 07FF
		 */
		uint32_t temp = (bridgeValue[2] << 3) + (bridgeValue[3] >> 5);
		temp *= 2000;
		temp /= 2048; // just a guess at this point...
		temp -= 500;
		sprintf((char *)msg,"  T: %2d.%01d C  ", (uint16_t)(temp / 10), (uint16_t)(temp % 10));
		BSP_LCD_DisplayStringAt(0, BSP_LCD_GetYSize()/2 + 95, msg, CENTER_MODE);
		osDelay(200);
		c += 1;
	}
  /* USER CODE END 5 */
}

/* USER CODE BEGIN Header_StartTaskI2C */
/**
* @brief Function implementing the grabI2CTask thread.
* @param argument: Not used
* @retval None
*/
/*
	* Status Bits (2 MSB of Output Data Packet) Definition
	* 00 - Normal Operation. Good Data Packet
	* 01 - Reserved
	* 10 - Stale Data. Data has been fetched since last measurement cycle.
	* 11 - Fault Detected
*/
/*
 *   | Action            | Byte 1            |  Byte 2   |   Byte 3    |  Byte 4    | Notes
 * --+-------------------+-------------------+-----------+-------------+------------+-------------------------
 *   | Put sensor into   | [7 bit address *] |           |             |            | Data must be
 * 1 | command mode      |        +          |   0xA0    |    0x00     |   0x00     | sent within 6ms
 *   |                   | [Write bit = 0]   |           |             |            | of power up
 * --+-------------------+-------------------+-----------+-------------+------------+-------------------------
 *   | Command to read   | [7 bit address *] |           |             |            |
 * 2 | EEPROM word 02    |        +          |   0x02    |    0x00     |   0x00     |
 *   | from sensor       | [Write bit = 0]   |           |             |            |
 * --+-------------------+-------------------+-----------+-------------+------------+-------------------------
 *   | Fetch EEPROM      | [7 bit address *] |   0x5A    |   Word 02   |  Word 02   |
 * 3 | word 02           |        +          | (response | [bits 15:8] | [bits 7:0] |
 *   |                   | [Read bit = 1]    |  byte)    |             |            |
 * --+-------------------+-------------------+-----------+-------------+------------+-------------------------
 *   | Modify Word 02    |                   |           |             |            | Bits [9:3]: I2C address
 * 4 | in user           |                   |           |             |            | required Bits [12:10]:
 *   | software          |                   |           |             |            | 011 (communication lock)
 * --+-------------------+-------------------+-----------+-------------+------------+-------------------------
 *   | Write new version | [7 bit address *] |           |   Word 02   |  Word 02   |
 * 5 | of Word 02 to     |        +          |   0x42    | [bits 15:8] | [bits 7:0] |
 *   | sensor EEPROM     | [Write bit = 0]   |           |             |            |
 * --+-------------------+-------------------+-----------+-------------+------------+-------------------------
 *   | Exit command mode | [7 bit address *] |           |             |            |
 * 6 | & start normal    |        +          |   0x80    |    0x00     |   0x00     |
 *   | operating mode    | [Write bit = 0]   |           |             |            |
 * --+-------------------+-------------------+-----------+-------------+------------+-------------------------
 */
/*
 * I2C Address
 * Code Device Address (hex)
 *  X    Analog Output*
 *  0    0x28*
 *  1    0x36
 *  2    0x46
 *  3    0x48
 *  4    0x51
 */
/*
 * Original value in word 02 : 0x5A 0x0D     0x46
 *                             0x5A 00001101 01000110
 *                                  000                - EEPROM lock
 *                                     011             - communication address lock
 *                                        01 01000     - address 7 bits
 *                                                11   - diagnostic config
 *                                                  0  - SPI clock polarity
 */
/* USER CODE END Header_StartTaskI2C */
void StartTaskI2C(void const * argument)
{
  /* USER CODE BEGIN StartTaskI2C */
	HAL_UART_Receive_DMA(&huart1, u1rx, 64);
	unsigned int u1cc = __HAL_DMA_GET_COUNTER(huart1.hdmarx);
	const uint32_t I2C_Timeout = I2Cx_TIMEOUT_MAX;
	const int nbAddress = 5;
	const uint8_t address[5] = { 0x28, 0x36, 0x46, 0x48, 0x51 };
	HAL_StatusTypeDef res;
	uint8_t detected = 0;
	uint8_t counted = 0;
	uint8_t dataBuf[4];
	int inLen = 0;
	int hb = 0;
	counts = 0;
	errs = 0;
	memset(bridgeValue,0,2);
	my_printf("\r\nStarting Run on %s\r\n# ", tskKERNEL_VERSION_NUMBER);
	// Now see what we do with cell
	for(;;)
	{
		int len = UART_Receive(input + inLen, u1rx, &huart1, &u1cc, 64);
		if (len > 0)
		{
			my_printf("%.*s", len, input + inLen);
			inLen += len;
			if (input[inLen - 1] == '\r')
			{
				int cmdLen = inLen - 1;
				my_printf("\nReceived command '%.*s'\r\n", cmdLen, input);
				inLen = 0;
				if (strncmp((char *) input, "UART", cmdLen) == 0)
					my_printf("u1rc = %u u1hrc = %u u1tc = %u u1htc = %u u1ec = %u u1ic = %u u1cc = %u\r\n# ", u1rc, u1hrc, u1tc, u1htc, u1ec, u1ic, u1cc);
				else if (strncmp((char *) input, "done", cmdLen) == 0)
				{
					my_printf("\nSetup done - now releasing read task\r\n# ");
					HAL_GPIO_WritePin(GPIOC, Sensor_PWR_Pin, GPIO_PIN_SET);
					HAL_Delay(10);
					// Indicate to the readI2C task that we are done
					if (counted == 0)
					{
						LCdev[0] = 0x28 << 1;
						LCcnt = 1;
					}
					else
						LCcnt = counted;
					break;
				}
				else if (strncmp((char *) input, "scan", cmdLen) == 0)
				{
					/* Power up load cell and detect it */
					detected = 0;
					counted = 0;
					for (unsigned int i = 0; i < nbAddress; i++)
					{
						uint8_t d = address[i] << 1;
						res = powerup_and_read(&hi2c3, d, dataBuf, I2C_Timeout);
						HAL_GPIO_WritePin(GPIOC, Sensor_PWR_Pin, GPIO_PIN_RESET);
						if (res == HAL_OK && dataBuf[0] == 0x5A)
						{
							uint8_t a = (dataBuf[1] >> 2) & 3;
							uint8_t b = ((dataBuf[1] & 3) << 5) | (dataBuf[2] >> 3);
							my_printf("Scan 0x%02X - received 0x%02X 0x%02X 0x%02X => %u 0x%02X\r\n", address[i], dataBuf[0], dataBuf[1], dataBuf[2], a, b);
							detected |= 1 << i;
							LCdev[counted++] = d;
						} else {
							my_printf("Scan 0x%02X - empty\r\n", address[i]);
						}
						HAL_Delay(10);
					}
					my_printf("Scan completed - found %u device%s - flags 0x%02X\r\n# ", counted, counted > 1 ? "s" : "", detected);
				}
				else if (strncmp((char *) input, "set ", 4) == 0 && cmdLen == 6)
				{
					/* WARNING - writing bad data to the EEPROM can render the sensor unusable...  */
					/*
					 * From ZSC31014 datasheet
					 *
					 *  Command Byte    Third and                                                                    Processing
					 * 8 Command Bits  Fourth Bytes    Description       Time ††
					 *    (Hex)          16 Data                          4MHz/1MHz
					 *                  Bits(Hex)
					 * 00HEX to 13HEX  0000HEX       EEPROM Read of addresses 00HEX to 13HEX.
					 *                               After this command has been sent and executed, a data
					 *                               fetch of three bytes must be performed. The first byte will be     10μs
					 *                               a response byte, which should be a 5AHEX, and then the next
					 *                               two bytes will be the EEPROM data.
					 * 40HEX to 53HEX  YYYYHEX       Write to EEPROM addresses 00HEX to 13HEX.
					 *                 (Y= data)     If the command is an EEPROM write, then the 16 bits of             15ms
					 *                               data sent will be written to the address specified in the 6
					 *                               LSBs of the command byte.
					 * 80HEX           0000HEX       Start_NOM => Ends Command Mode and transitions to
					 *                               Normal Operation Mode. When a Start_NOM command is              15ms if EEPROM
					 *                               executed, a flag is checked to see if EEPROM was                signature is
					 *                               programmed during Command Mode. If so, the device will          updated;
					 *                               regenerate the checksum and update the signature                10μs otherwise
					 *                               EEPROM word.
					 * A0HEX           0000HEX       Start_CM => Start Command Mode; used to enter
					 *                               Command Mode. Start_CM is only valid during the power-on           10μs
					 *                               command window.
					 */
					/* Set I2C address to new value */
					int old = input[4] - '0';
					int new = input[5] - '0';
					if (old < 0 || old > 4 || new < 0 || new > 4 || (detected & (1 << old)) == 0)
						my_printf("Something is wrong... old = %d, new = %d, detected = %d\r\n", old, new, detected);
					else
					{
						uint8_t d = address[old] << 1;
						res = powerup_and_read(&hi2c3, d, dataBuf, I2C_Timeout);
						uint8_t a = (dataBuf[1] >> 2) & 3;
						uint8_t b = ((dataBuf[1] & 3) << 5) | (dataBuf[2] >> 3);
						my_printf("Got %d 0x%02X 0x%02X 0x%02X %u 0x%02X\r\n", res, dataBuf[0], dataBuf[1], dataBuf[2], a, b);
						if (res == HAL_OK && dataBuf[0] == 0x5A)
						{
							write_word(&hi2c3, d, dataBuf,
												 2,
												 0x0C | (address[new] >> 5),
												 0x06 | ((address[new] << 3) & 0xff),
												 I2C_Timeout);
							exit_command_mode(&hi2c3, d, dataBuf, I2C_Timeout);
							osDelay(50);
							HAL_GPIO_WritePin(GPIOC, Sensor_PWR_Pin, GPIO_PIN_RESET);
							my_printf("Will now pause 10 seconds\r\n");
							osDelay(10000);
							HAL_GPIO_WritePin(GPIOC, Sensor_PWR_Pin, GPIO_PIN_SET);
							HAL_Delay(10);
							d = address[new] << 1;
							memset(dataBuf,0,4);
							res = HAL_I2C_Master_Receive(&hi2c3, d | 1, dataBuf, 4, I2C_Timeout);
							my_printf("Retrieved 0x%02X 0x%02X 0x%02X 0x%02X %d with new address 0x%02X\r\n", dataBuf[0], dataBuf[1], dataBuf[2], dataBuf[3], res, address[new]);
							osDelay(50);
							memset(dataBuf,0,4);
							res = HAL_I2C_Master_Receive(&hi2c3, d | 1, dataBuf, 4, I2C_Timeout);
							my_printf("Retrieved 0x%02X 0x%02X 0x%02X 0x%02X %d with new address 0x%02X\r\n", dataBuf[0], dataBuf[1], dataBuf[2], dataBuf[3], res, address[new]);
							if (res == HAL_OK)
								my_printf("Set new I2C address completed successfully - 0x%02X -> 0x%02X\r\n", address[old], address[new]);
							else
								my_printf("Set new I2C address failed : %d\r\n", res);
						} else {
							my_printf("Power up check failed : %d 0x%02X 0x%02X 0x%02X %u 0x%02X\r\n", res, dataBuf[0], dataBuf[1], dataBuf[2], a, b);
						}
						HAL_GPIO_WritePin(GPIOC, Sensor_PWR_Pin, GPIO_PIN_RESET);
						detected = 0;
						counted = 0;
					}
					my_printf("# ");
				}
				else if (strncmp((char *) input, "reset", cmdLen) == 0)
				{
					/*
					 * 3.2.10 General call address
					 * 0000 0110 (06h) — Reset and write programmable part of slave address by hardware.
					 * On receiving this 2-byte sequence, all devices designed to respond to the general call
					 * address reset and take in the programmable part of their address.
					 */
					dataBuf[0] = 0x06;
					HAL_GPIO_WritePin(GPIOC, Sensor_PWR_Pin, GPIO_PIN_SET);
					HAL_Delay(3);
					res = HAL_I2C_Master_Transmit(&hi2c3, 0, dataBuf, 1, I2C_Timeout);
					HAL_Delay(10);
					HAL_GPIO_WritePin(GPIOC, Sensor_PWR_Pin, GPIO_PIN_RESET);
					my_printf("General call with reset done - res = %d\r\n# ", res);
				}
				else if (strncmp((char *) input, "read", cmdLen) == 0)
				{
					/* read EEPROM values */
					uint8_t d = LCdev[0];
					res = powerup_and_read(&hi2c3, d, dataBuf, I2C_Timeout);
					uint8_t a = (dataBuf[1] >> 2) & 3;
					uint8_t b = ((dataBuf[1] & 3) << 5) | (dataBuf[2] >> 3);
					my_printf("Reading from 0x%02X\r\nGot %d 0x%02X 0x%02X 0x%02X %u 0x%02X\r\n", d >> 1, res, dataBuf[0], dataBuf[1], dataBuf[2], a, b);
					if (res == HAL_OK && dataBuf[0] == 0x5A)
					{
						for (uint8_t a = 0; a < 0x14; a++)
						{
							res = read_cell(&hi2c3, d, a, dataBuf, I2C_Timeout);
							my_printf(" 0x%02X : 0x%02X 0x%02X 0x%02X %d\r\n", a, dataBuf[0], dataBuf[1], dataBuf[2], res);
							if (res != HAL_OK || dataBuf[0] != 0x5A)
								break;
						}
					}
					HAL_GPIO_WritePin(GPIOC, Sensor_PWR_Pin, GPIO_PIN_RESET);
					my_printf("# ");
				}
				else if (strncmp((char *) input, "probe", cmdLen) == 0)
				{
					uint8_t d = LCdev[0];
					my_printf("\nProbing twice\r\n");
					HAL_GPIO_WritePin(GPIOC, Sensor_PWR_Pin, GPIO_PIN_SET);
					HAL_Delay(10);
					for (unsigned int i = 0; i < 4; i++)
					{
						memset(dataBuf,0,4);
						res = HAL_I2C_Master_Receive(&hi2c3, d | 1, dataBuf, 4, I2C_Timeout);
						my_printf("Read %d at 0x%02X (%d) :", i, d >> 1, res);
						int status = dataBuf[0] >> 6;
						int w = ((dataBuf[0] & 0x3f) << 8) | dataBuf[1];
						int t = (dataBuf[2] << 3) | (dataBuf[3] >> 5);
						my_printf(" status %u - weight %u temperature %u\r\n", status, w, t);
						osDelay(1000);
					}
					HAL_GPIO_WritePin(GPIOC, Sensor_PWR_Pin, GPIO_PIN_RESET);
					osDelay(50);
					res = powerup_and_read(&hi2c3, d, dataBuf, I2C_Timeout);
					uint8_t a = (dataBuf[1] >> 2) & 3;
					uint8_t b = ((dataBuf[1] & 3) << 5) | (dataBuf[2] >> 3);
					my_printf("Got %d 0x%02X 0x%02X 0x%02X %u 0x%02X\r\n", res, dataBuf[0], dataBuf[1], dataBuf[2], a, b);
					if (res == HAL_OK && dataBuf[0] == 0x5A)
					{
						exit_command_mode(&hi2c3, d, dataBuf, I2C_Timeout);
						for (unsigned int i = 0; i < 4; i++)
						{
							memset(dataBuf,0,4);
							res = HAL_I2C_Master_Receive(&hi2c3, d | 1, dataBuf, 4, I2C_Timeout);
							my_printf("Read %d at 0x%02X (%d) :", i, d >> 1, res);
							int status = dataBuf[0] >> 6;
							int w = ((dataBuf[0] & 0x3f) << 8) | dataBuf[1];
							int t = (dataBuf[2] << 3) | (dataBuf[3] >> 5);
							my_printf(" status %u - weight %u temperature %u\r\n", status, w, t);
							osDelay(1000);
						}
					}
					HAL_GPIO_WritePin(GPIOC, Sensor_PWR_Pin, GPIO_PIN_RESET);
					my_printf("# ");
				}
				else if (strncmp((char *) input, "ID", cmdLen) == 0)
				{
					/* does not seem to work on my device... */
					/*
					 * The Device ID is read-only, hard-wired in the device and can be accessed as follows:
					 * 1. START condition
					 * 2. The master sends the Reserved Device ID I2C-bus address followed by the R/W bit
					 *    set to ‘0’ (write): ‘1111 1000’.
					 * 3. The master sends the I2C-bus slave address of the slave device it must identify. The
					 *    LSB is a ‘Don’t care’ value. Only one device must acknowledge this byte (the one that
					 *    has the I2C-bus slave address).
					 * 4. The master sends a Re-START condition.
					 *    Remark: A STOP condition followed by a START condition resets the slave state
					 *    machine and the Device ID Read cannot be performed. Also, a STOP condition or a
					 *    Re-START condition followed by an access to another slave device resets the slave
					 *    state machine and the Device ID Read cannot be performed.
					 * 5. The master sends the Reserved Device ID I2C-bus address followed by the R/W bit
					 *    set to ‘1’ (read): ‘1111 1001’.
					 * 6. The Device ID Read can be done, starting with the 12 manufacturer bits (first byte +
					 *    four MSBs of the second byte), followed by the nine part identification bits (four LSBs
					 *    of the second byte + five MSBs of the third byte), and then the three die revision bits
					 *    (three LSBs of the third byte).
					 * 7. The master ends the reading sequence by NACKing the last byte, thus resetting the
					 *    slave device state machine and allowing the master to send the STOP condition.
					 */
					my_printf("\nGetting Device ID\r\n");
					HAL_GPIO_WritePin(GPIOC, Sensor_PWR_Pin, GPIO_PIN_SET);
					HAL_Delay(10);
					for (unsigned int i = 0; i < 5; i++)
					{
						int d = address[i] << 1;
						memset(dataBuf,0,3);
						res = HAL_I2C_Mem_Read(&hi2c3, 0xF8, d, 1, dataBuf, 3, I2C_Timeout);
						my_printf("%u - 0x%02X : 0x%02X 0x%02X 0x%02X %d\r\n", i, d >> 1, dataBuf[0], dataBuf[1], dataBuf[2], res);
						if (res == HAL_OK)
						{
							int m = (dataBuf[0] << 4) | (dataBuf[1] >> 4);
							int p = ((int) dataBuf[1] << 5) | (dataBuf[2] >> 3);
							my_printf("  Manufacturer %u (0x%03X) Part %u (0x%03X) Die revision %u\r\n", m, m, p, p, dataBuf[2] & 0x7);
						}
					}
					HAL_GPIO_WritePin(GPIOC, Sensor_PWR_Pin, GPIO_PIN_RESET);
					my_printf("# ");
				}
#if 0
				else if (strncmp((char *) input, "prog", cmdLen) == 0)
				{
					/* Try to revive my part */
					uint8_t d = LCdev[0];
					my_printf("\nProgramming device\r\n");
					res = powerup_and_read(&hi2c3, d, dataBuf, I2C_Timeout);
					uint8_t a = (dataBuf[1] >> 2) & 3;
					uint8_t b = ((dataBuf[1] & 3) << 5) | (dataBuf[2] >> 3);
					my_printf("Got %d 0x%02X 0x%02X 0x%02X %u 0x%02X\r\n", res, dataBuf[0], dataBuf[1], dataBuf[2], a, b);
					if (res == HAL_OK && dataBuf[0] == 0x5A)
					{
						write_word(&hi2c3, d, dataBuf, 0x00, 0x01, 0x0A, I2C_Timeout);
						write_word(&hi2c3, d, dataBuf, 0x03, 0xE6, 0x86, I2C_Timeout);
						write_word(&hi2c3, d, dataBuf, 0x04, 0x24, 0xAB, I2C_Timeout);
						write_word(&hi2c3, d, dataBuf, 0x05, 0x07, 0xC2, I2C_Timeout);
						write_word(&hi2c3, d, dataBuf, 0x08, 0x02, 0x91, I2C_Timeout);
						write_word(&hi2c3, d, dataBuf, 0x0A, 0xED, 0x42, I2C_Timeout);
						write_word(&hi2c3, d, dataBuf, 0x0B, 0x53, 0x90, I2C_Timeout);
						write_word(&hi2c3, d, dataBuf, 0x0D, 0x1F, 0xB0, I2C_Timeout);
						write_word(&hi2c3, d, dataBuf, 0x0E, 0x00, 0x2D, I2C_Timeout);
						write_word(&hi2c3, d, dataBuf, 0x0F, 0x0A, 0xA1, I2C_Timeout);
						write_word(&hi2c3, d, dataBuf, 0x10, 0x04, 0x99, I2C_Timeout);
						write_word(&hi2c3, d, dataBuf, 0x13, 0x08, 0x3C, I2C_Timeout);
						// now go to normal mode and compute checksum
						exit_command_mode(&hi2c3, d, dataBuf, I2C_Timeout);
						osDelay(50);
						HAL_GPIO_WritePin(GPIOC, Sensor_PWR_Pin, GPIO_PIN_RESET);
						my_printf("Will now pause 10 seconds\r\n");
						osDelay(10000);
						HAL_GPIO_WritePin(GPIOC, Sensor_PWR_Pin, GPIO_PIN_SET);
						HAL_Delay(10);
						memset(dataBuf,0,4);
						res = HAL_I2C_Master_Receive(&hi2c3, d | 1, dataBuf, 4, I2C_Timeout);
						my_printf("Retrieved 0x%02X 0x%02X 0x%02X 0x%02X %d\r\n", dataBuf[0], dataBuf[1], dataBuf[2], dataBuf[3], res);
						osDelay(50);
						memset(dataBuf,0,4);
						res = HAL_I2C_Master_Receive(&hi2c3, d | 1, dataBuf, 4, I2C_Timeout);
						my_printf("Retrieved 0x%02X 0x%02X 0x%02X 0x%02X %d\r\n", dataBuf[0], dataBuf[1], dataBuf[2], dataBuf[3], res);
					}
					HAL_GPIO_WritePin(GPIOC, Sensor_PWR_Pin, GPIO_PIN_RESET);
					my_printf("# ");
				}
#endif
				else
					my_printf("Unknown command\r\n# ");
			}
		}
		osDelay(50);
	}
	/* Infinite loop */
	for(;;)
	{
		hb += 1;
		if (hb > 20)
		{
			HAL_GPIO_TogglePin(LD3_GPIO_Port, LD3_Pin); // toggle green led as heartbeat
			hb = 0;
		}
		int len = UART_Receive(input + inLen, u1rx, &huart1, &u1cc, 64);
		if (len > 0)
		{
			my_printf("%.*s", len, input + inLen);
			inLen += len;
			if (input[inLen - 1] == '\r')
			{
				int cmdLen = inLen - 1;
				my_printf("\nReceived command '%.*s'\r\n# ", cmdLen, input);
				inLen = 0;
				if (strncmp((char *) input, "UART", cmdLen) == 0)
					my_printf("u1rc = %u u1hrc = %u u1tc = %u u1htc = %u u1ec = %u u1ic = %u u1cc = %u\r\n# ", u1rc, u1hrc, u1tc, u1htc, u1ec, u1ic, u1cc);
			}
		}
		osDelay(50);
	}
  /* USER CODE END StartTaskI2C */
}

void readI2C(void const * argument)
{
  /* USER CODE BEGIN readI2C */
	const uint32_t I2C_Timeout = I2Cx_TIMEOUT_MAX;
	HAL_StatusTypeDef res;
	uint8_t dataBuf[4];
	/* Infinite loop */
	for(;;)
	{
		if (LCcnt > 0)
		{
			// all on the same bus... need to read sequentially
			// maybe reorganize to send update request followed by actual read of data
			//  currently alternates between stale and valid data
			for (unsigned int i = 0; i < LCcnt; i++)
			{
				memset(dataBuf, 0, 4);
				res = HAL_I2C_Master_Receive(&hi2c3, LCdev[i] | 1, dataBuf, 4, I2C_Timeout);
				if (res != HAL_OK)
					errs += 1;
				else
				{
					uint8_t status = (dataBuf[0] >> 6) & 0x3;
					if (status == 0)
					{
						counts += 1;
						memcpy(bridgeValue + i * 4, dataBuf, 4);
					} else if (status == 2)
						stale += 1;
					else
						bridgeValue[3] = status;
				}
			}
			osDelay(50);
		}
		else
			osDelay(1000);
	}
  /* USER CODE END readI2C */
}

void HAL_TIM_PeriodElapsedCallback(TIM_HandleTypeDef *htim)
{
  if (htim->Instance == TIM6) {
    HAL_IncTick();
  }
}

void Error_Handler(void)
{
}

/************************ (C) COPYRIGHT STMicroelectronics *****END OF FILE****/

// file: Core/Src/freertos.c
/* USER CODE BEGIN Header */
/**
  ******************************************************************************
  * File Name          : freertos.c
  * Description        : Code for freertos applications
  ******************************************************************************
  * @attention
  *
  * <h2><center>&copy; Copyright (c) 2020 STMicroelectronics.
  * All rights reserved.</center></h2>
  *
  * This software component is licensed by ST under Ultimate Liberty license
  * SLA0044, the "License"; You may not use this file except in compliance with
  * the License. You may obtain a copy of the License at:
  *                             www.st.com/SLA0044
  *
  ******************************************************************************
  */
/* USER CODE END Header */

#include "FreeRTOS.h"
#include "task.h"
#include "main.h"

/* GetIdleTaskMemory prototype (linked to static allocation support) */
void vApplicationGetIdleTaskMemory( StaticTask_t **ppxIdleTaskTCBBuffer, StackType_t **ppxIdleTaskStackBuffer, uint32_t *pulIdleTaskStackSize );

/* Hook prototypes */
void vApplicationStackOverflowHook(TaskHandle_t xTask, signed char *pcTaskName);
void vApplicationMallocFailedHook(void);

/* USER CODE BEGIN 4 */
__weak void vApplicationStackOverflowHook(TaskHandle_t xTask, signed char *pcTaskName)
{
   /* Run time stack overflow checking is performed if
   configCHECK_FOR_STACK_OVERFLOW is defined to 1 or 2. This hook function is
   called if a stack overflow is detected. */
	while ( 1 )
	{
		HAL_GPIO_TogglePin(LD3_GPIO_Port, LD3_Pin); // toggle green led
		HAL_Delay(100);
		HAL_GPIO_TogglePin(LD4_GPIO_Port, LD4_Pin); // toggle red led
		HAL_Delay(100);
	}
}
/* USER CODE END 4 */

/* USER CODE BEGIN 5 */
__weak void vApplicationMallocFailedHook(void)
{
   /* vApplicationMallocFailedHook() will only be called if
   configUSE_MALLOC_FAILED_HOOK is set to 1 in FreeRTOSConfig.h. It is a hook
   function that will get called if a call to pvPortMalloc() fails.
   pvPortMalloc() is called internally by the kernel whenever a task, queue,
   timer or semaphore is created. It is also called by various parts of the
   demo application. If heap_1.c or heap_2.c are used, then the size of the
   heap available to pvPortMalloc() is defined by configTOTAL_HEAP_SIZE in
   FreeRTOSConfig.h, and the xPortGetFreeHeapSize() API function can be used
   to query the size of free heap space that remains (although it does not
   provide information on how the remaining heap might be fragmented). */
	while ( 1 )
	{
		HAL_GPIO_TogglePin(LD3_GPIO_Port, LD3_Pin); // toggle green led
		HAL_Delay(200);
		HAL_GPIO_TogglePin(LD4_GPIO_Port, LD4_Pin); // toggle red led
		HAL_Delay(100);
	}
}
/* USER CODE END 5 */

/* USER CODE BEGIN GET_IDLE_TASK_MEMORY */
static StaticTask_t xIdleTaskTCBBuffer;
static StackType_t xIdleStack[configMINIMAL_STACK_SIZE];

void vApplicationGetIdleTaskMemory( StaticTask_t **ppxIdleTaskTCBBuffer, StackType_t **ppxIdleTaskStackBuffer, uint32_t *pulIdleTaskStackSize )
{
  *ppxIdleTaskTCBBuffer = &xIdleTaskTCBBuffer;
  *ppxIdleTaskStackBuffer = &xIdleStack[0];
  *pulIdleTaskStackSize = configMINIMAL_STACK_SIZE;
  /* place for user code */
}
/* USER CODE END GET_IDLE_TASK_MEMORY */

/************************ (C) COPYRIGHT STMicroelectronics *****END OF FILE****/
